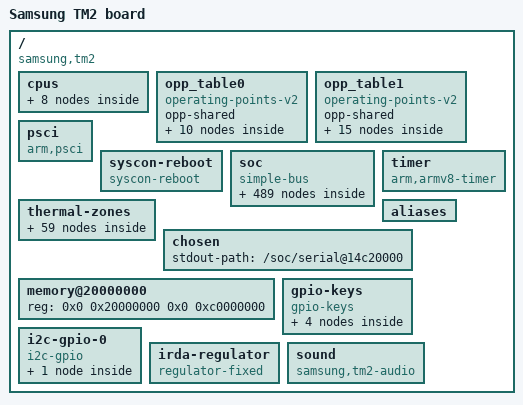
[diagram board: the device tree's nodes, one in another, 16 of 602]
/dts-v1/;

/ {
	compatible = "samsung,tm2", "samsung,exynos5433";
	#address-cells = <0x2>;
	#size-cells = <0x2>;
	interrupt-parent = <0x1>;
	model = "Samsung TM2 board";

	cpus {
		#address-cells = <0x1>;
		#size-cells = <0x0>;

		cpu@100 {
			device_type = "cpu";
			compatible = "arm,cortex-a53", "arm,armv8";
			enable-method = "psci";
			reg = <0x100>;
			clock-frequency = "M|m";
			clocks = <0x2 0x1e>;
			clock-names = "apolloclk";
			operating-points-v2 = <0x3>;
			#cooling-cells = <0x2>;
			cpu-supply = <0x4>;
			linux,phandle = <0x90>;
			phandle = <0x90>;
		};

		cpu@101 {
			device_type = "cpu";
			compatible = "arm,cortex-a53", "arm,armv8";
			enable-method = "psci";
			reg = <0x101>;
			clock-frequency = "M|m";
			operating-points-v2 = <0x3>;
			#cooling-cells = <0x2>;
			linux,phandle = <0x9b>;
			phandle = <0x9b>;
		};

		cpu@102 {
			device_type = "cpu";
			compatible = "arm,cortex-a53", "arm,armv8";
			enable-method = "psci";
			reg = <0x102>;
			clock-frequency = "M|m";
			operating-points-v2 = <0x3>;
			#cooling-cells = <0x2>;
			linux,phandle = <0x9c>;
			phandle = <0x9c>;
		};

		cpu@103 {
			device_type = "cpu";
			compatible = "arm,cortex-a53", "arm,armv8";
			enable-method = "psci";
			reg = <0x103>;
			clock-frequency = "M|m";
			operating-points-v2 = <0x3>;
			#cooling-cells = <0x2>;
			linux,phandle = <0x9d>;
			phandle = <0x9d>;
		};

		cpu@0 {
			device_type = "cpu";
			compatible = "arm,cortex-a57", "arm,armv8";
			enable-method = "psci";
			reg = <0x0>;
			clock-frequency = <0x713fb300>;
			clocks = <0x5 0x27>;
			clock-names = "atlasclk";
			operating-points-v2 = <0x6>;
			#cooling-cells = <0x2>;
			cpu-supply = <0x7>;
			linux,phandle = <0x85>;
			phandle = <0x85>;
		};

		cpu@1 {
			device_type = "cpu";
			compatible = "arm,cortex-a57", "arm,armv8";
			enable-method = "psci";
			reg = <0x1>;
			clock-frequency = <0x713fb300>;
			operating-points-v2 = <0x6>;
			#cooling-cells = <0x2>;
			linux,phandle = <0x9e>;
			phandle = <0x9e>;
		};

		cpu@2 {
			device_type = "cpu";
			compatible = "arm,cortex-a57", "arm,armv8";
			enable-method = "psci";
			reg = <0x2>;
			clock-frequency = <0x713fb300>;
			operating-points-v2 = <0x6>;
			#cooling-cells = <0x2>;
			linux,phandle = <0x9f>;
			phandle = <0x9f>;
		};

		cpu@3 {
			device_type = "cpu";
			compatible = "arm,cortex-a57", "arm,armv8";
			enable-method = "psci";
			reg = <0x3>;
			clock-frequency = <0x713fb300>;
			operating-points-v2 = <0x6>;
			#cooling-cells = <0x2>;
			linux,phandle = <0xa0>;
			phandle = <0xa0>;
		};
	};

	opp_table0 {
		compatible = "operating-points-v2";
		opp-shared;
		linux,phandle = <0x3>;
		phandle = <0x3>;

		opp-400000000 {
			opp-hz = <0x0 0x17d78400>;
			opp-microvolt = <0xdbba0>;
		};

		opp-500000000 {
			opp-hz = <0x0 0x1dcd6500>;
			opp-microvolt = <0xe1d48>;
		};

		opp-600000000 {
			opp-hz = <0x0 0x23c34600>;
			opp-microvolt = <0xe7ef0>;
		};

		opp-700000000 {
			opp-hz = <0x0 0x29b92700>;
			opp-microvolt = <0xee098>;
		};

		opp-800000000 {
			opp-hz = <0x0 0x2faf0800>;
			opp-microvolt = <0xf4240>;
		};

		opp-900000000 {
			opp-hz = <0x0 0x35a4e900>;
			opp-microvolt = <0x100590>;
		};

		opp-1000000000 {
			opp-hz = <0x0 0x3b9aca00>;
			opp-microvolt = <0x106738>;
		};

		opp-1100000000 {
			opp-hz = <0x0 0x4190ab00>;
			opp-microvolt = <0x10f9b4>;
		};

		opp-1200000000 {
			opp-hz = <0x0 0x47868c00>;
			opp-microvolt = <0x10f9b4>;
		};

		opp-1300000000 {
			opp-hz = <0x0 0x4d7c6d00>;
			opp-microvolt = <0x118c30>;
		};
	};

	opp_table1 {
		compatible = "operating-points-v2";
		opp-shared;
		linux,phandle = <0x6>;
		phandle = <0x6>;

		opp-500000000 {
			opp-hz = <0x0 0x1dcd6500>;
			opp-microvolt = <0xdbba0>;
		};

		opp-600000000 {
			opp-hz = <0x0 0x23c34600>;
			opp-microvolt = <0xdbba0>;
		};

		opp-700000000 {
			opp-hz = <0x0 0x29b92700>;
			opp-microvolt = <0xdec74>;
		};

		opp-800000000 {
			opp-hz = <0x0 0x2faf0800>;
			opp-microvolt = <0xdec74>;
		};

		opp-900000000 {
			opp-hz = <0x0 0x35a4e900>;
			opp-microvolt = <0xe4e1c>;
		};

		opp-1000000000 {
			opp-hz = <0x0 0x3b9aca00>;
			opp-microvolt = <0xee098>;
		};

		opp-1100000000 {
			opp-hz = <0x0 0x4190ab00>;
			opp-microvolt = <0xf7314>;
		};

		opp-1200000000 {
			opp-hz = <0x0 0x47868c00>;
			opp-microvolt = <0xfd4bc>;
		};

		opp-1300000000 {
			opp-hz = <0x0 0x4d7c6d00>;
			opp-microvolt = <0x103664>;
		};

		opp-1400000000 {
			opp-hz = <0x0 0x53724e00>;
			opp-microvolt = <0x10980c>;
		};

		opp-1500000000 {
			opp-hz = <0x0 0x59682f00>;
			opp-microvolt = <0x112a88>;
		};

		opp-1600000000 {
			opp-hz = <0x0 0x5f5e1000>;
			opp-microvolt = <0x115b5c>;
		};

		opp-1700000000 {
			opp-hz = <0x0 0x6553f100>;
			opp-microvolt = <0x11edd8>;
		};

		opp-1800000000 {
			opp-hz = <0x0 0x6b49d200>;
			opp-microvolt = <0x128054>;
		};

		opp-1900000000 {
			opp-hz = <0x0 0x713fb300>;
			opp-microvolt = <0x1343a4>;
		};
	};

	psci {
		compatible = "arm,psci";
		method = "smc";
		cpu_off = <0x84000002>;
		cpu_on = <0xc4000003>;
	};

	syscon-reboot {
		compatible = "syscon-reboot";
		regmap = <0x8>;
		offset = <0x400>;
		mask = <0x1>;
		linux,phandle = <0xa1>;
		phandle = <0xa1>;
	};

	soc {
		compatible = "simple-bus";
		#address-cells = <0x1>;
		#size-cells = <0x1>;
		ranges = <0x0 0x0 0x0 0x18000000>;
		linux,phandle = <0xa2>;
		phandle = <0xa2>;

		chipid@10000000 {
			compatible = "samsung,exynos4210-chipid";
			reg = <0x10000000 0x100>;
		};

		xxti {
			compatible = "fixed-clock";
			clock-output-names = "oscclk";
			#clock-cells = <0x0>;
			clock-frequency = <0x16e3600>;
			linux,phandle = <0x9>;
			phandle = <0x9>;
		};

		clock-controller@10030000 {
			compatible = "samsung,exynos5433-cmu-top";
			reg = <0x10030000 0x1000>;
			#clock-cells = <0x1>;
			clock-names = "oscclk", "sclk_mphy_pll", "sclk_mfc_pll", "sclk_bus_pll";
			clocks = <0x9 0xa 0xb 0xb 0xc5 0xb 0xc6>;
			linux,phandle = <0xc>;
			phandle = <0xc>;
		};

		clock-controller@10fc0000 {
			compatible = "samsung,exynos5433-cmu-cpif";
			reg = <0x10fc0000 0x1000>;
			#clock-cells = <0x1>;
			clock-names = "oscclk";
			clocks = <0x9>;
			linux,phandle = <0xa>;
			phandle = <0xa>;
		};

		clock-controller@105b0000 {
			compatible = "samsung,exynos5433-cmu-mif";
			reg = <0x105b0000 0x2000>;
			#clock-cells = <0x1>;
			clock-names = "oscclk", "sclk_mphy_pll";
			clocks = <0x9 0xa 0xb>;
			linux,phandle = <0xb>;
			phandle = <0xb>;
		};

		clock-controller@14c80000 {
			compatible = "samsung,exynos5433-cmu-peric";
			reg = <0x14c80000 0x1000>;
			#clock-cells = <0x1>;
			linux,phandle = <0x3c>;
			phandle = <0x3c>;
		};

		clock-controller@10040000 {
			compatible = "samsung,exynos5433-cmu-peris";
			reg = <0x10040000 0x1000>;
			#clock-cells = <0x1>;
			linux,phandle = <0x13>;
			phandle = <0x13>;
		};

		clock-controller@156e0000 {
			compatible = "samsung,exynos5433-cmu-fsys";
			reg = <0x156e0000 0x1000>;
			#clock-cells = <0x1>;
			clock-names = "oscclk", "sclk_ufs_mphy", "aclk_fsys_200", "sclk_pcie_100_fsys", "sclk_ufsunipro_fsys", "sclk_mmc2_fsys", "sclk_mmc1_fsys", "sclk_mmc0_fsys", "sclk_usbhost30_fsys", "sclk_usbdrd30_fsys";
			clocks = <0x9 0xa 0xb 0xc 0xca 0xc 0xe4 0xc 0xe5 0xc 0xcb 0xc 0xcc 0xc 0xcd 0xc 0xe6 0xc 0xe7>;
			assigned-clocks = <0xc 0x3b 0xc 0x3a 0xd 0x9 0xd 0x8 0xd 0x10 0xd 0xa 0xd 0x11 0xd 0xb 0xc 0x8f 0xc 0x8d>;
			assigned-clock-parents = <0xc 0xf 0xc 0xf 0xc 0xe7 0xc 0xe6 0xd 0x1a 0xd 0x1c 0xd 0x19 0xd 0x1b>;
			assigned-clock-rates = <0x0 0x0 0x0 0x0 0x0 0x0 0x0 0x0 0x3f9c2e0 0x3f9c2e0>;
			linux,phandle = <0xd>;
			phandle = <0xd>;
		};

		clock-controller@12460000 {
			compatible = "samsung,exynos5433-cmu-g2d";
			reg = <0x12460000 0x1000>;
			#clock-cells = <0x1>;
			clock-names = "oscclk", "aclk_g2d_266", "aclk_g2d_400";
			clocks = <0x9 0xc 0xdc 0xc 0xdd>;
			linux,phandle = <0xa3>;
			phandle = <0xa3>;
		};

		clock-controller@13b90000 {
			compatible = "samsung,exynos5433-cmu-disp";
			reg = <0x13b90000 0x1000>;
			#clock-cells = <0x1>;
			clock-names = "oscclk", "sclk_dsim1_disp", "sclk_dsim0_disp", "sclk_dsd_disp", "sclk_decon_tv_eclk_disp", "sclk_decon_vclk_disp", "sclk_decon_eclk_disp", "sclk_decon_tv_vclk_disp", "aclk_disp_333";
			clocks = <0x9 0xb 0xb9 0xb 0xbf 0xb 0xc0 0xb 0xc1 0xb 0xc2 0xb 0xc3 0xb 0xba 0xb 0x98>;
			assigned-clocks = <0xe 0x1 0xb 0x48 0xe 0xa 0xe 0x4 0xe 0x11 0xe 0x8 0xe 0x14 0xe 0xe 0xe 0xd 0xe 0x2 0xb 0x24 0xe 0x6 0xe 0x12>;
			assigned-clock-parents = <0x0 0x0 0xb 0x98 0xb 0xbf 0xe 0x4 0xb 0xc3 0xe 0x8 0xe 0x73 0xe 0x72 0xe 0x1 0xb 0xb 0xb 0xc1 0xe 0x6>;
			assigned-clock-rates = <0xee6b280 0x17d78400>;
			linux,phandle = <0xe>;
			phandle = <0xe>;
		};

		clock-controller@114c0000 {
			compatible = "samsung,exynos5433-cmu-aud";
			reg = <0x114c0000 0x1000>;
			#clock-cells = <0x1>;
			clock-names = "oscclk", "fout_aud_pll";
			clocks = <0x9 0xc 0x2>;
			assigned-clocks = <0xf 0x1>;
			assigned-clock-parents = <0xc 0x2>;
			linux,phandle = <0xf>;
			phandle = <0xf>;
		};

		clock-controller@13600000 {
			compatible = "samsung,exynos5433-cmu-bus0";
			reg = <0x13600000 0x1000>;
			#clock-cells = <0x1>;
			clock-names = "aclk_bus0_400";
			clocks = <0xc 0xe0>;
			linux,phandle = <0xa4>;
			phandle = <0xa4>;
		};

		clock-controller@14800000 {
			compatible = "samsung,exynos5433-cmu-bus1";
			reg = <0x14800000 0x1000>;
			#clock-cells = <0x1>;
			clock-names = "aclk_bus1_400";
			clocks = <0xc 0xe1>;
			linux,phandle = <0xa5>;
			phandle = <0xa5>;
		};

		clock-controller@13400000 {
			compatible = "samsung,exynos5433-cmu-bus2";
			reg = <0x13400000 0x1000>;
			#clock-cells = <0x1>;
			clock-names = "oscclk", "aclk_bus2_400";
			clocks = <0x9 0xb 0x97>;
			linux,phandle = <0xa6>;
			phandle = <0xa6>;
		};

		clock-controller@14aa0000 {
			compatible = "samsung,exynos5433-cmu-g3d";
			reg = <0x14aa0000 0x2000>;
			#clock-cells = <0x1>;
			clock-names = "oscclk", "aclk_g3d_400";
			clocks = <0x9 0xc 0xde>;
			linux,phandle = <0xa7>;
			phandle = <0xa7>;
		};

		clock-controller@13cf0000 {
			compatible = "samsung,exynos5433-cmu-gscl";
			reg = <0x13cf0000 0x1000>;
			#clock-cells = <0x1>;
			clock-names = "oscclk", "aclk_gscl_111", "aclk_gscl_333";
			clocks = <0x9 0xc 0xe8 0xc 0xe9>;
			assigned-clocks = <0x10 0x1 0x10 0x2>;
			assigned-clock-parents = <0xc 0xe8 0xc 0xe9>;
			linux,phandle = <0x10>;
			phandle = <0x10>;
		};

		clock-controller@11900000 {
			compatible = "samsung,exynos5433-cmu-apollo";
			reg = <0x11900000 0x2000>;
			#clock-cells = <0x1>;
			clock-names = "oscclk", "sclk_bus_pll_apollo";
			clocks = <0x9 0xb 0xc7>;
			linux,phandle = <0x2>;
			phandle = <0x2>;
		};

		clock-controller@11800000 {
			compatible = "samsung,exynos5433-cmu-atlas";
			reg = <0x11800000 0x2000>;
			#clock-cells = <0x1>;
			clock-names = "oscclk", "sclk_bus_pll_atlas";
			clocks = <0x9 0xb 0xc8>;
			linux,phandle = <0x5>;
			phandle = <0x5>;
		};

		clock-controller@105d0000 {
			compatible = "samsung,exynos5433-cmu-mscl";
			reg = <0x150d0000 0x1000>;
			#clock-cells = <0x1>;
			clock-names = "oscclk", "sclk_jpeg_mscl", "aclk_mscl_400";
			clocks = <0x9 0xc 0xea 0xc 0xeb>;
			assigned-clocks = <0x11 0x2 0x11 0x1 0x11 0x3 0xc 0x1e>;
			assigned-clock-parents = <0xc 0xeb 0xc 0xea 0x11 0x1 0xc 0xf>;
			linux,phandle = <0x11>;
			phandle = <0x11>;
		};

		clock-controller@15280000 {
			compatible = "samsung,exynos5433-cmu-mfc";
			reg = <0x15280000 0x1000>;
			#clock-cells = <0x1>;
			clock-names = "oscclk", "aclk_mfc_400";
			clocks = <0x9 0xc 0xec>;
			assigned-clocks = <0x12 0x1>;
			assigned-clock-parents = <0xc 0xec>;
			linux,phandle = <0x12>;
			phandle = <0x12>;
		};

		clock-controller@14f80000 {
			compatible = "samsung,exynos5433-cmu-hevc";
			reg = <0x14f80000 0x1000>;
			#clock-cells = <0x1>;
			clock-names = "oscclk", "aclk_hevc_400";
			clocks = <0x9 0xc 0xed>;
			linux,phandle = <0xa8>;
			phandle = <0xa8>;
		};

		clock-controller@146d0000 {
			compatible = "samsung,exynos5433-cmu-isp";
			reg = <0x146d0000 0x1000>;
			#clock-cells = <0x1>;
			clock-names = "oscclk", "aclk_isp_dis_400", "aclk_isp_400";
			clocks = <0x9 0xc 0xee 0xc 0xef>;
			linux,phandle = <0xa9>;
			phandle = <0xa9>;
		};

		clock-controller@120d0000 {
			compatible = "samsung,exynos5433-cmu-cam0";
			reg = <0x120d0000 0x1000>;
			#clock-cells = <0x1>;
			clock-names = "oscclk", "aclk_cam0_333", "aclk_cam0_400", "aclk_cam0_552";
			clocks = <0x9 0xc 0xf0 0xc 0xf1 0xc 0xf2>;
			linux,phandle = <0xaa>;
			phandle = <0xaa>;
		};

		clock-controller@145d0000 {
			compatible = "samsung,exynos5433-cmu-cam1";
			reg = <0x145d0000 0x1000>;
			#clock-cells = <0x1>;
			clock-names = "oscclk", "sclk_isp_uart_cam1", "sclk_isp_spi1_cam1", "sclk_isp_spi0_cam1", "aclk_cam1_333", "aclk_cam1_400", "aclk_cam1_552";
			clocks = <0x9 0xc 0xfa 0xc 0xfb 0xc 0xfc 0xc 0xf3 0xc 0xf4 0xc 0xf5>;
			linux,phandle = <0xab>;
			phandle = <0xab>;
		};

		tmu@10060000 {
			compatible = "samsung,exynos5433-tmu";
			reg = <0x10060000 0x200>;
			interrupts = <0x0 0x5f 0x4>;
			clocks = <0x13 0x3 0x13 0x23>;
			clock-names = "tmu_apbif", "tmu_sclk";
			#thermal-sensor-cells = <0x0>;
			samsung,tmu_gain = <0x8>;
			samsung,tmu_reference_voltage = <0x10>;
			samsung,tmu_noise_cancel_mode = <0x4>;
			samsung,tmu_efuse_value = <0x4b>;
			samsung,tmu_min_efuse_value = <0x28>;
			samsung,tmu_max_efuse_value = <0x96>;
			samsung,tmu_first_point_trim = <0x19>;
			samsung,tmu_second_point_trim = <0x55>;
			samsung,tmu_default_temp_offset = <0x32>;
			status = "okay";
			vtmu-supply = <0x14>;
			linux,phandle = <0x83>;
			phandle = <0x83>;
		};

		tmu@10068000 {
			compatible = "samsung,exynos5433-tmu";
			reg = <0x10068000 0x200>;
			interrupts = <0x0 0x60 0x4>;
			clocks = <0x13 0x3 0x13 0x23>;
			clock-names = "tmu_apbif", "tmu_sclk";
			#thermal-sensor-cells = <0x0>;
			samsung,tmu_gain = <0x8>;
			samsung,tmu_reference_voltage = <0x10>;
			samsung,tmu_noise_cancel_mode = <0x4>;
			samsung,tmu_efuse_value = <0x4b>;
			samsung,tmu_min_efuse_value = <0x28>;
			samsung,tmu_max_efuse_value = <0x96>;
			samsung,tmu_first_point_trim = <0x19>;
			samsung,tmu_second_point_trim = <0x55>;
			samsung,tmu_default_temp_offset = <0x32>;
			status = "disabled";
			linux,phandle = <0x8c>;
			phandle = <0x8c>;
		};

		tmu@10070000 {
			compatible = "samsung,exynos5433-tmu";
			reg = <0x10070000 0x200>;
			interrupts = <0x0 0x63 0x4>;
			clocks = <0x13 0x2 0x13 0x22>;
			clock-names = "tmu_apbif", "tmu_sclk";
			#thermal-sensor-cells = <0x0>;
			samsung,tmu_gain = <0x8>;
			samsung,tmu_reference_voltage = <0x17>;
			samsung,tmu_noise_cancel_mode = <0x4>;
			samsung,tmu_efuse_value = <0x4b>;
			samsung,tmu_min_efuse_value = <0x28>;
			samsung,tmu_max_efuse_value = <0x96>;
			samsung,tmu_first_point_trim = <0x19>;
			samsung,tmu_second_point_trim = <0x55>;
			samsung,tmu_default_temp_offset = <0x32>;
			samsung,tmu_mux_addr = <0x6>;
			status = "okay";
			vtmu-supply = <0x14>;
			linux,phandle = <0x8d>;
			phandle = <0x8d>;
		};

		tmu@10078000 {
			compatible = "samsung,exynos5433-tmu";
			reg = <0x10078000 0x200>;
			interrupts = <0x0 0x73 0x4>;
			clocks = <0x13 0x2 0x13 0x22>;
			clock-names = "tmu_apbif", "tmu_sclk";
			#thermal-sensor-cells = <0x0>;
			samsung,tmu_gain = <0x8>;
			samsung,tmu_reference_voltage = <0x10>;
			samsung,tmu_noise_cancel_mode = <0x4>;
			samsung,tmu_efuse_value = <0x4b>;
			samsung,tmu_min_efuse_value = <0x28>;
			samsung,tmu_max_efuse_value = <0x96>;
			samsung,tmu_first_point_trim = <0x19>;
			samsung,tmu_second_point_trim = <0x55>;
			samsung,tmu_default_temp_offset = <0x32>;
			status = "okay";
			vtmu-supply = <0x14>;
			linux,phandle = <0x8e>;
			phandle = <0x8e>;
		};

		tmu@1007c000 {
			compatible = "samsung,exynos5433-tmu";
			reg = <0x1007c000 0x200>;
			interrupts = <0x0 0x5e 0x4>;
			clocks = <0x13 0x2 0x13 0x22>;
			clock-names = "tmu_apbif", "tmu_sclk";
			#thermal-sensor-cells = <0x0>;
			samsung,tmu_gain = <0x8>;
			samsung,tmu_reference_voltage = <0x10>;
			samsung,tmu_noise_cancel_mode = <0x4>;
			samsung,tmu_efuse_value = <0x4b>;
			samsung,tmu_min_efuse_value = <0x28>;
			samsung,tmu_max_efuse_value = <0x96>;
			samsung,tmu_first_point_trim = <0x19>;
			samsung,tmu_second_point_trim = <0x55>;
			samsung,tmu_default_temp_offset = <0x32>;
			status = "disabled";
			linux,phandle = <0x95>;
			phandle = <0x95>;
		};

		mct@101c0000 {
			compatible = "samsung,exynos4210-mct";
			reg = <0x101c0000 0x800>;
			interrupts = <0x0 0x66 0x4 0x0 0x67 0x4 0x0 0x68 0x4 0x0 0x69 0x4 0x0 0x6a 0x4 0x0 0x6b 0x4 0x0 0x6c 0x4 0x0 0x6d 0x4 0x0 0x6e 0x4 0x0 0x6f 0x4 0x0 0x70 0x4 0x0 0x71 0x4>;
			clocks = <0x9 0x13 0x9>;
			clock-names = "fin_pll", "mct";
		};

		ppmu@10480000 {
			compatible = "samsung,exynos-ppmu-v2";
			reg = <0x10480000 0x2000>;
			status = "disabled";
			linux,phandle = <0xac>;
			phandle = <0xac>;
		};

		ppmu@10490000 {
			compatible = "samsung,exynos-ppmu-v2";
			reg = <0x10490000 0x2000>;
			status = "okay";
			linux,phandle = <0xad>;
			phandle = <0xad>;

			events {

				ppmu-event0-d0-general {
					event-name = "ppmu-event0-d0-general";
					linux,phandle = <0x7b>;
					phandle = <0x7b>;
				};
			};
		};

		ppmu@104b0000 {
			compatible = "samsung,exynos-ppmu-v2";
			reg = <0x104b0000 0x2000>;
			status = "disabled";
			linux,phandle = <0xae>;
			phandle = <0xae>;
		};

		ppmu@104c0000 {
			compatible = "samsung,exynos-ppmu-v2";
			reg = <0x104c0000 0x2000>;
			status = "okay";
			linux,phandle = <0xaf>;
			phandle = <0xaf>;

			events {

				ppmu-event0-d1-general {
					event-name = "ppmu-event0-d1-general";
					linux,phandle = <0x7c>;
					phandle = <0x7c>;
				};
			};
		};

		pinctrl@10580000 {
			compatible = "samsung,exynos5433-pinctrl";
			reg = <0x10580000 0x1a20 0x11090000 0x100>;
			pinctrl-names = "default";
			pinctrl-0 = <0x15>;
			linux,phandle = <0xb0>;
			phandle = <0xb0>;

			wakeup-interrupt-controller {
				compatible = "samsung,exynos7-wakeup-eint";
				interrupts = <0x0 0x10 0x4>;
			};

			gpa0 {
				gpio-controller;
				#gpio-cells = <0x2>;
				interrupt-controller;
				interrupt-parent = <0x1>;
				interrupts = <0x0 0x0 0x4 0x0 0x1 0x4 0x0 0x2 0x4 0x0 0x3 0x4 0x0 0x4 0x4 0x0 0x5 0x4 0x0 0x6 0x4 0x0 0x7 0x4>;
				#interrupt-cells = <0x2>;
				linux,phandle = <0x44>;
				phandle = <0x44>;
			};

			gpa1 {
				gpio-controller;
				#gpio-cells = <0x2>;
				interrupt-controller;
				interrupt-parent = <0x1>;
				interrupts = <0x0 0x8 0x4 0x0 0x9 0x4 0x0 0xa 0x4 0x0 0xb 0x4 0x0 0xc 0x4 0x0 0xd 0x4 0x0 0xe 0x4 0x0 0xf 0x4>;
				#interrupt-cells = <0x2>;
				linux,phandle = <0x55>;
				phandle = <0x55>;
			};

			gpa2 {
				gpio-controller;
				#gpio-cells = <0x2>;
				interrupt-controller;
				#interrupt-cells = <0x2>;
				linux,phandle = <0x72>;
				phandle = <0x72>;
			};

			gpa3 {
				gpio-controller;
				#gpio-cells = <0x2>;
				interrupt-controller;
				#interrupt-cells = <0x2>;
				linux,phandle = <0x33>;
				phandle = <0x33>;
			};

			gpf1 {
				gpio-controller;
				#gpio-cells = <0x2>;
				interrupt-controller;
				#interrupt-cells = <0x2>;
				linux,phandle = <0x2e>;
				phandle = <0x2e>;
			};

			gpf2 {
				gpio-controller;
				#gpio-cells = <0x2>;
				interrupt-controller;
				#interrupt-cells = <0x2>;
				linux,phandle = <0xb1>;
				phandle = <0xb1>;
			};

			gpf3 {
				gpio-controller;
				#gpio-cells = <0x2>;
				interrupt-controller;
				#interrupt-cells = <0x2>;
				linux,phandle = <0xb2>;
				phandle = <0xb2>;
			};

			gpf4 {
				gpio-controller;
				#gpio-cells = <0x2>;
				interrupt-controller;
				#interrupt-cells = <0x2>;
				linux,phandle = <0xb3>;
				phandle = <0xb3>;
			};

			gpf5 {
				gpio-controller;
				#gpio-cells = <0x2>;
				interrupt-controller;
				#interrupt-cells = <0x2>;
				linux,phandle = <0xb4>;
				phandle = <0xb4>;
			};

			initial-state {
				linux,phandle = <0x15>;
				phandle = <0x15>;

				gpa0-0 {
					samsung,pins = "gpa0-0";
					samsung,pin-function = <0x0>;
					samsung,pin-pud = <0x1>;
					samsung,pin-drv = <0x0>;
				};

				gpa0-1 {
					samsung,pins = "gpa0-1";
					samsung,pin-function = <0x0>;
					samsung,pin-pud = <0x0>;
					samsung,pin-drv = <0x0>;
				};

				gpa0-2 {
					samsung,pins = "gpa0-2";
					samsung,pin-function = <0x0>;
					samsung,pin-pud = <0x1>;
					samsung,pin-drv = <0x0>;
				};

				gpa0-3 {
					samsung,pins = "gpa0-3";
					samsung,pin-function = <0x0>;
					samsung,pin-pud = <0x0>;
					samsung,pin-drv = <0x0>;
				};

				gpa0-4 {
					samsung,pins = "gpa0-4";
					samsung,pin-function = <0x0>;
					samsung,pin-pud = <0x0>;
					samsung,pin-drv = <0x0>;
				};

				gpa0-5 {
					samsung,pins = "gpa0-5";
					samsung,pin-function = <0x0>;
					samsung,pin-pud = <0x1>;
					samsung,pin-drv = <0x0>;
				};

				gpa0-6 {
					samsung,pins = "gpa0-6";
					samsung,pin-function = <0x0>;
					samsung,pin-pud = <0x0>;
					samsung,pin-drv = <0x0>;
				};

				gpa0-7 {
					samsung,pins = "gpa0-7";
					samsung,pin-function = <0x0>;
					samsung,pin-pud = <0x0>;
					samsung,pin-drv = <0x0>;
				};

				gpa1-0 {
					samsung,pins = "gpa1-0";
					samsung,pin-function = <0x0>;
					samsung,pin-pud = <0x3>;
					samsung,pin-drv = <0x0>;
				};

				gpa1-1 {
					samsung,pins = "gpa1-1";
					samsung,pin-function = <0x0>;
					samsung,pin-pud = <0x3>;
					samsung,pin-drv = <0x0>;
				};

				gpa1-2 {
					samsung,pins = "gpa1-2";
					samsung,pin-function = <0x0>;
					samsung,pin-pud = <0x0>;
					samsung,pin-drv = <0x0>;
				};

				gpa1-3 {
					samsung,pins = "gpa1-3";
					samsung,pin-function = <0x0>;
					samsung,pin-pud = <0x1>;
					samsung,pin-drv = <0x0>;
				};

				gpa1-4 {
					samsung,pins = "gpa1-4";
					samsung,pin-function = <0x0>;
					samsung,pin-pud = <0x1>;
					samsung,pin-drv = <0x0>;
				};

				gpa1-5 {
					samsung,pins = "gpa1-5";
					samsung,pin-function = <0x0>;
					samsung,pin-pud = <0x0>;
					samsung,pin-drv = <0x0>;
				};

				gpa1-6 {
					samsung,pins = "gpa1-6";
					samsung,pin-function = <0x0>;
					samsung,pin-pud = <0x0>;
					samsung,pin-drv = <0x0>;
				};

				gpa1-7 {
					samsung,pins = "gpa1-7";
					samsung,pin-function = <0x0>;
					samsung,pin-pud = <0x0>;
					samsung,pin-drv = <0x0>;
				};

				gpa2-0 {
					samsung,pins = "gpa2-0";
					samsung,pin-function = <0x0>;
					samsung,pin-pud = <0x0>;
					samsung,pin-drv = <0x0>;
				};

				gpa2-1 {
					samsung,pins = "gpa2-1";
					samsung,pin-function = <0x0>;
					samsung,pin-pud = <0x0>;
					samsung,pin-drv = <0x0>;
				};

				gpa2-2 {
					samsung,pins = "gpa2-2";
					samsung,pin-function = <0x0>;
					samsung,pin-pud = <0x0>;
					samsung,pin-drv = <0x0>;
				};

				gpa2-3 {
					samsung,pins = "gpa2-3";
					samsung,pin-function = <0x0>;
					samsung,pin-pud = <0x1>;
					samsung,pin-drv = <0x0>;
				};

				gpa2-4 {
					samsung,pins = "gpa2-4";
					samsung,pin-function = <0x0>;
					samsung,pin-pud = <0x0>;
					samsung,pin-drv = <0x0>;
				};

				gpa2-5 {
					samsung,pins = "gpa2-5";
					samsung,pin-function = <0x0>;
					samsung,pin-pud = <0x1>;
					samsung,pin-drv = <0x0>;
				};

				gpa2-6 {
					samsung,pins = "gpa2-6";
					samsung,pin-function = <0x0>;
					samsung,pin-pud = <0x1>;
					samsung,pin-drv = <0x0>;
				};

				gpa2-7 {
					samsung,pins = "gpa2-7";
					samsung,pin-function = <0x0>;
					samsung,pin-pud = <0x0>;
					samsung,pin-drv = <0x0>;
				};

				gpa3-0 {
					samsung,pins = "gpa3-0";
					samsung,pin-function = <0x0>;
					samsung,pin-pud = <0x1>;
					samsung,pin-drv = <0x0>;
				};

				gpa3-1 {
					samsung,pins = "gpa3-1";
					samsung,pin-function = <0x0>;
					samsung,pin-pud = <0x1>;
					samsung,pin-drv = <0x0>;
				};

				gpa3-2 {
					samsung,pins = "gpa3-2";
					samsung,pin-function = <0x0>;
					samsung,pin-pud = <0x0>;
					samsung,pin-drv = <0x0>;
				};

				gpa3-3 {
					samsung,pins = "gpa3-3";
					samsung,pin-function = <0x0>;
					samsung,pin-pud = <0x1>;
					samsung,pin-drv = <0x0>;
				};

				gpa3-4 {
					samsung,pins = "gpa3-4";
					samsung,pin-function = <0x0>;
					samsung,pin-pud = <0x0>;
					samsung,pin-drv = <0x0>;
				};

				gpa3-5 {
					samsung,pins = "gpa3-5";
					samsung,pin-function = <0x0>;
					samsung,pin-pud = <0x1>;
					samsung,pin-drv = <0x0>;
				};

				gpa3-6 {
					samsung,pins = "gpa3-6";
					samsung,pin-function = <0x0>;
					samsung,pin-pud = <0x1>;
					samsung,pin-drv = <0x0>;
				};

				gpa3-7 {
					samsung,pins = "gpa3-7";
					samsung,pin-function = <0x0>;
					samsung,pin-pud = <0x1>;
					samsung,pin-drv = <0x0>;
				};

				gpf1-0 {
					samsung,pins = "gpf1-0";
					samsung,pin-function = <0x0>;
					samsung,pin-pud = <0x0>;
					samsung,pin-drv = <0x0>;
				};

				gpf1-1 {
					samsung,pins = "gpf1-1";
					samsung,pin-function = <0x0>;
					samsung,pin-pud = <0x0>;
					samsung,pin-drv = <0x0>;
				};

				gpf1-2 {
					samsung,pins = "gpf1-2";
					samsung,pin-function = <0x0>;
					samsung,pin-pud = <0x1>;
					samsung,pin-drv = <0x0>;
				};

				gpf1-4 {
					samsung,pins = "gpf1-4";
					samsung,pin-function = <0x0>;
					samsung,pin-pud = <0x3>;
					samsung,pin-drv = <0x0>;
				};

				gpf1-5 {
					samsung,pins = "gpf1-5";
					samsung,pin-function = <0x1>;
					samsung,pin-pud = <0x0>;
					samsung,pin-drv = <0x0>;
				};

				gpf1-6 {
					samsung,pins = "gpf1-6";
					samsung,pin-function = <0x0>;
					samsung,pin-pud = <0x1>;
					samsung,pin-drv = <0x0>;
				};

				gpf1-7 {
					samsung,pins = "gpf1-7";
					samsung,pin-function = <0x0>;
					samsung,pin-pud = <0x1>;
					samsung,pin-drv = <0x0>;
				};

				gpf2-0 {
					samsung,pins = "gpf2-0";
					samsung,pin-function = <0x0>;
					samsung,pin-pud = <0x1>;
					samsung,pin-drv = <0x0>;
				};

				gpf2-1 {
					samsung,pins = "gpf2-1";
					samsung,pin-function = <0x0>;
					samsung,pin-pud = <0x1>;
					samsung,pin-drv = <0x0>;
				};

				gpf2-2 {
					samsung,pins = "gpf2-2";
					samsung,pin-function = <0x0>;
					samsung,pin-pud = <0x1>;
					samsung,pin-drv = <0x0>;
				};

				gpf2-3 {
					samsung,pins = "gpf2-3";
					samsung,pin-function = <0x0>;
					samsung,pin-pud = <0x1>;
					samsung,pin-drv = <0x0>;
				};

				gpf3-0 {
					samsung,pins = "gpf3-0";
					samsung,pin-function = <0x0>;
					samsung,pin-pud = <0x1>;
					samsung,pin-drv = <0x0>;
				};

				gpf3-1 {
					samsung,pins = "gpf3-1";
					samsung,pin-function = <0x0>;
					samsung,pin-pud = <0x1>;
					samsung,pin-drv = <0x0>;
				};

				gpf3-2 {
					samsung,pins = "gpf3-2";
					samsung,pin-function = <0x0>;
					samsung,pin-pud = <0x0>;
					samsung,pin-drv = <0x0>;
				};

				gpf3-3 {
					samsung,pins = "gpf3-3";
					samsung,pin-function = <0x0>;
					samsung,pin-pud = <0x1>;
					samsung,pin-drv = <0x0>;
				};

				gpf4-0 {
					samsung,pins = "gpf4-0";
					samsung,pin-function = <0x0>;
					samsung,pin-pud = <0x1>;
					samsung,pin-drv = <0x0>;
				};

				gpf4-1 {
					samsung,pins = "gpf4-1";
					samsung,pin-function = <0x0>;
					samsung,pin-pud = <0x1>;
					samsung,pin-drv = <0x0>;
				};

				gpf4-2 {
					samsung,pins = "gpf4-2";
					samsung,pin-function = <0x0>;
					samsung,pin-pud = <0x1>;
					samsung,pin-drv = <0x0>;
				};

				gpf4-3 {
					samsung,pins = "gpf4-3";
					samsung,pin-function = <0x0>;
					samsung,pin-pud = <0x1>;
					samsung,pin-drv = <0x0>;
				};

				gpf4-4 {
					samsung,pins = "gpf4-4";
					samsung,pin-function = <0x0>;
					samsung,pin-pud = <0x1>;
					samsung,pin-drv = <0x0>;
				};

				gpf4-5 {
					samsung,pins = "gpf4-5";
					samsung,pin-function = <0x0>;
					samsung,pin-pud = <0x1>;
					samsung,pin-drv = <0x0>;
				};

				gpf4-6 {
					samsung,pins = "gpf4-6";
					samsung,pin-function = <0x0>;
					samsung,pin-pud = <0x1>;
					samsung,pin-drv = <0x0>;
				};

				gpf4-7 {
					samsung,pins = "gpf4-7";
					samsung,pin-function = <0x0>;
					samsung,pin-pud = <0x1>;
					samsung,pin-drv = <0x0>;
				};

				gpf5-0 {
					samsung,pins = "gpf5-0";
					samsung,pin-function = <0x0>;
					samsung,pin-pud = <0x1>;
					samsung,pin-drv = <0x0>;
				};

				gpf5-1 {
					samsung,pins = "gpf5-1";
					samsung,pin-function = <0x0>;
					samsung,pin-pud = <0x1>;
					samsung,pin-drv = <0x0>;
				};

				gpf5-2 {
					samsung,pins = "gpf5-2";
					samsung,pin-function = <0x0>;
					samsung,pin-pud = <0x1>;
					samsung,pin-drv = <0x0>;
				};

				gpf5-3 {
					samsung,pins = "gpf5-3";
					samsung,pin-function = <0x0>;
					samsung,pin-pud = <0x1>;
					samsung,pin-drv = <0x0>;
				};

				gpf5-4 {
					samsung,pins = "gpf5-4";
					samsung,pin-function = <0x1>;
					samsung,pin-pud = <0x0>;
					samsung,pin-drv = <0x0>;
				};

				gpf5-5 {
					samsung,pins = "gpf5-5";
					samsung,pin-function = <0x0>;
					samsung,pin-pud = <0x1>;
					samsung,pin-drv = <0x0>;
				};

				gpf5-6 {
					samsung,pins = "gpf5-6";
					samsung,pin-function = <0x0>;
					samsung,pin-pud = <0x1>;
					samsung,pin-drv = <0x0>;
				};

				gpf5-7 {
					samsung,pins = "gpf5-7";
					samsung,pin-function = <0x0>;
					samsung,pin-pud = <0x1>;
					samsung,pin-drv = <0x0>;
				};
			};

			te_irq {
				samsung,pins = "gpf1-3";
				samsung,pin-function = <0xf>;
				linux,phandle = <0x29>;
				phandle = <0x29>;
			};
		};

		pinctrl@114b0000 {
			compatible = "samsung,exynos5433-pinctrl";
			reg = <0x114b0000 0x1000>;
			interrupts = <0x0 0x44 0x4>;
			linux,phandle = <0xb5>;
			phandle = <0xb5>;

			gpz0 {
				gpio-controller;
				#gpio-cells = <0x2>;
				interrupt-controller;
				#interrupt-cells = <0x2>;
				linux,phandle = <0xb6>;
				phandle = <0xb6>;
			};

			gpz1 {
				gpio-controller;
				#gpio-cells = <0x2>;
				interrupt-controller;
				#interrupt-cells = <0x2>;
				linux,phandle = <0xb7>;
				phandle = <0xb7>;
			};

			i2s0-bus {
				samsung,pins = "gpz0-0", "gpz0-1", "gpz0-2", "gpz0-3", "gpz0-4", "gpz0-5", "gpz0-6";
				samsung,pin-function = <0x2>;
				samsung,pin-pud = <0x0>;
				samsung,pin-drv = <0x0>;
				linux,phandle = <0x78>;
				phandle = <0x78>;
			};

			pcm0-bus {
				samsung,pins = "gpz1-0", "gpz1-1", "gpz1-2", "gpz1-3";
				samsung,pin-function = <0x3>;
				samsung,pin-pud = <0x0>;
				samsung,pin-drv = <0x0>;
				linux,phandle = <0xb8>;
				phandle = <0xb8>;
			};

			uart-aud-bus {
				samsung,pins = "gpz1-3", "gpz1-2", "gpz1-1", "gpz1-0";
				samsung,pin-function = <0x2>;
				samsung,pin-pud = <0x0>;
				samsung,pin-drv = <0x0>;
				linux,phandle = <0x79>;
				phandle = <0x79>;
			};
		};

		pinctrl@10fe0000 {
			compatible = "samsung,exynos5433-pinctrl";
			reg = <0x10fe0000 0x1000>;
			interrupts = <0x0 0xb3 0x4>;
			pinctrl-names = "default";
			pinctrl-0 = <0x16>;
			linux,phandle = <0xb9>;
			phandle = <0xb9>;

			gpv6 {
				gpio-controller;
				#gpio-cells = <0x2>;
				interrupt-controller;
				#interrupt-cells = <0x2>;
				linux,phandle = <0xba>;
				phandle = <0xba>;
			};

			initial-state {
				linux,phandle = <0x16>;
				phandle = <0x16>;

				gpv6-0 {
					samsung,pins = "gpv6-0";
					samsung,pin-function = <0x0>;
					samsung,pin-pud = <0x1>;
					samsung,pin-drv = <0x0>;
				};

				gpv6-1 {
					samsung,pins = "gpv6-1";
					samsung,pin-function = <0x0>;
					samsung,pin-pud = <0x1>;
					samsung,pin-drv = <0x0>;
				};
			};
		};

		pinctrl@14ca0000 {
			compatible = "samsung,exynos5433-pinctrl";
			reg = <0x14ca0000 0x1000>;
			interrupts = <0x0 0x19d 0x4>;
			pinctrl-names = "default";
			pinctrl-0 = <0x17>;
			linux,phandle = <0xbb>;
			phandle = <0xbb>;

			gpj2 {
				gpio-controller;
				#gpio-cells = <0x2>;
				interrupt-controller;
				#interrupt-cells = <0x2>;
				linux,phandle = <0xbc>;
				phandle = <0xbc>;
			};

			initial-state {
				linux,phandle = <0x17>;
				phandle = <0x17>;

				gpj2-0 {
					samsung,pins = "gpj2-0";
					samsung,pin-function = <0x0>;
					samsung,pin-pud = <0x1>;
					samsung,pin-drv = <0x0>;
				};

				gpj2-1 {
					samsung,pins = "gpj2-1";
					samsung,pin-function = <0x0>;
					samsung,pin-pud = <0x1>;
					samsung,pin-drv = <0x0>;
				};

				gpj2-2 {
					samsung,pins = "gpj2-2";
					samsung,pin-function = <0x0>;
					samsung,pin-pud = <0x1>;
					samsung,pin-drv = <0x0>;
				};
			};
		};

		pinctrl@14cb0000 {
			compatible = "samsung,exynos5433-pinctrl";
			reg = <0x14cb0000 0x1000>;
			interrupts = <0x0 0x19e 0x4>;
			linux,phandle = <0xbd>;
			phandle = <0xbd>;

			gpd5 {
				gpio-controller;
				#gpio-cells = <0x2>;
				interrupt-controller;
				#interrupt-cells = <0x2>;
				linux,phandle = <0xbe>;
				phandle = <0xbe>;
			};

			spi2-bus {
				samsung,pins = "gpd5-0", "gpd5-2", "gpd5-3";
				samsung,pin-function = <0x2>;
				samsung,pin-pud = <0x3>;
				samsung,pin-drv = <0x0>;
				linux,phandle = <0x49>;
				phandle = <0x49>;
			};

			hs-i2c6-bus {
				samsung,pins = "gpd5-3", "gpd5-2";
				samsung,pin-function = <0x4>;
				samsung,pin-pud = <0x3>;
				samsung,pin-drv = <0x0>;
				linux,phandle = <0x58>;
				phandle = <0x58>;
			};
		};

		pinctrl@15690000 {
			compatible = "samsung,exynos5433-pinctrl";
			reg = <0x15690000 0x1000>;
			interrupts = <0x0 0xe5 0x4>;
			pinctrl-names = "default";
			pinctrl-0 = <0x18>;
			linux,phandle = <0xbf>;
			phandle = <0xbf>;

			gph1 {
				gpio-controller;
				#gpio-cells = <0x2>;
				interrupt-controller;
				#interrupt-cells = <0x2>;
				linux,phandle = <0xc0>;
				phandle = <0xc0>;
			};

			gpr4 {
				gpio-controller;
				#gpio-cells = <0x2>;
				interrupt-controller;
				#interrupt-cells = <0x2>;
				linux,phandle = <0xc1>;
				phandle = <0xc1>;
			};

			gpr0 {
				gpio-controller;
				#gpio-cells = <0x2>;
				interrupt-controller;
				#interrupt-cells = <0x2>;
				linux,phandle = <0xc2>;
				phandle = <0xc2>;
			};

			gpr1 {
				gpio-controller;
				#gpio-cells = <0x2>;
				interrupt-controller;
				#interrupt-cells = <0x2>;
				linux,phandle = <0xc3>;
				phandle = <0xc3>;
			};

			gpr2 {
				gpio-controller;
				#gpio-cells = <0x2>;
				interrupt-controller;
				#interrupt-cells = <0x2>;
				linux,phandle = <0xc4>;
				phandle = <0xc4>;
			};

			gpr3 {
				gpio-controller;
				#gpio-cells = <0x2>;
				interrupt-controller;
				#interrupt-cells = <0x2>;
				linux,phandle = <0x97>;
				phandle = <0x97>;
			};

			sd0-clk {
				samsung,pins = "gpr0-0";
				samsung,pin-function = <0x2>;
				samsung,pin-pud = <0x0>;
				samsung,pin-drv = <0x3>;
				linux,phandle = <0x6b>;
				phandle = <0x6b>;
			};

			sd0-cmd {
				samsung,pins = "gpr0-1";
				samsung,pin-function = <0x2>;
				samsung,pin-pud = <0x0>;
				samsung,pin-drv = <0x3>;
				linux,phandle = <0x6c>;
				phandle = <0x6c>;
			};

			sd0-rdqs {
				samsung,pins = "gpr0-2";
				samsung,pin-function = <0x2>;
				samsung,pin-pud = <0x1>;
				samsung,pin-drv = <0x3>;
				linux,phandle = <0x71>;
				phandle = <0x71>;
			};

			sd0-qrdy {
				samsung,pins = "gpr0-3";
				samsung,pin-function = <0x2>;
				samsung,pin-pud = <0x1>;
				samsung,pin-drv = <0x3>;
				linux,phandle = <0x6d>;
				phandle = <0x6d>;
			};

			sd0-bus-width1 {
				samsung,pins = "gpr1-0";
				samsung,pin-function = <0x2>;
				samsung,pin-pud = <0x3>;
				samsung,pin-drv = <0x3>;
				linux,phandle = <0x6e>;
				phandle = <0x6e>;
			};

			sd0-bus-width4 {
				samsung,pins = "gpr1-1", "gpr1-2", "gpr1-3";
				samsung,pin-function = <0x2>;
				samsung,pin-pud = <0x3>;
				samsung,pin-drv = <0x3>;
				linux,phandle = <0x6f>;
				phandle = <0x6f>;
			};

			sd0-bus-width8 {
				samsung,pins = "gpr1-4", "gpr1-5", "gpr1-6", "gpr1-7";
				samsung,pin-function = <0x2>;
				samsung,pin-pud = <0x3>;
				samsung,pin-drv = <0x3>;
				linux,phandle = <0x70>;
				phandle = <0x70>;
			};

			sd1-clk {
				samsung,pins = "gpr2-0";
				samsung,pin-function = <0x2>;
				samsung,pin-pud = <0x0>;
				samsung,pin-drv = <0x3>;
				linux,phandle = <0xc5>;
				phandle = <0xc5>;
			};

			sd1-cmd {
				samsung,pins = "gpr2-1";
				samsung,pin-function = <0x2>;
				samsung,pin-pud = <0x0>;
				samsung,pin-drv = <0x3>;
				linux,phandle = <0xc6>;
				phandle = <0xc6>;
			};

			sd1-bus-width1 {
				samsung,pins = "gpr3-0";
				samsung,pin-function = <0x2>;
				samsung,pin-pud = <0x3>;
				samsung,pin-drv = <0x3>;
				linux,phandle = <0xc7>;
				phandle = <0xc7>;
			};

			sd1-bus-width4 {
				samsung,pins = "gpr3-1", "gpr3-2", "gpr3-3";
				samsung,pin-function = <0x2>;
				samsung,pin-pud = <0x3>;
				samsung,pin-drv = <0x3>;
				linux,phandle = <0xc8>;
				phandle = <0xc8>;
			};

			sd1-bus-width8 {
				samsung,pins = "gpr3-4", "gpr3-5", "gpr3-6", "gpr3-7";
				samsung,pin-function = <0x2>;
				samsung,pin-pud = <0x3>;
				samsung,pin-drv = <0x3>;
				linux,phandle = <0xc9>;
				phandle = <0xc9>;
			};

			pcie_bus {
				samsung,pins = "gpr3-4", "gpr3-5", "gpr3-6", "gpr3-7";
				samsung,pin-function = <0x3>;
				samsung,pin-pud = <0x3>;
				linux,phandle = <0xca>;
				phandle = <0xca>;
			};

			sd2-clk {
				samsung,pins = "gpr4-0";
				samsung,pin-function = <0x2>;
				samsung,pin-pud = <0x0>;
				samsung,pin-drv = <0x3>;
				linux,phandle = <0x73>;
				phandle = <0x73>;
			};

			sd2-cmd {
				samsung,pins = "gpr4-1";
				samsung,pin-function = <0x2>;
				samsung,pin-pud = <0x0>;
				samsung,pin-drv = <0x3>;
				linux,phandle = <0x74>;
				phandle = <0x74>;
			};

			sd2-cd {
				samsung,pins = "gpr4-2";
				samsung,pin-function = <0x2>;
				samsung,pin-pud = <0x3>;
				samsung,pin-drv = <0x3>;
				linux,phandle = <0xcb>;
				phandle = <0xcb>;
			};

			sd2-bus-width1 {
				samsung,pins = "gpr4-3";
				samsung,pin-function = <0x2>;
				samsung,pin-pud = <0x3>;
				samsung,pin-drv = <0x3>;
				linux,phandle = <0x75>;
				phandle = <0x75>;
			};

			sd2-bus-width4 {
				samsung,pins = "gpr4-4", "gpr4-5", "gpr4-6";
				samsung,pin-function = <0x2>;
				samsung,pin-pud = <0x3>;
				samsung,pin-drv = <0x3>;
				linux,phandle = <0x76>;
				phandle = <0x76>;
			};

			sd2-clk-output {
				samsung,pins = "gpr4-0";
				samsung,pin-function = <0x1>;
				samsung,pin-pud = <0x0>;
				samsung,pin-drv = <0x2>;
				linux,phandle = <0xcc>;
				phandle = <0xcc>;
			};

			sd2-cmd-output {
				samsung,pins = "gpr4-1";
				samsung,pin-function = <0x1>;
				samsung,pin-pud = <0x0>;
				samsung,pin-drv = <0x2>;
				linux,phandle = <0xcd>;
				phandle = <0xcd>;
			};

			initial-state {
				linux,phandle = <0x18>;
				phandle = <0x18>;

				gpr3-0 {
					samsung,pins = "gpr3-0";
					samsung,pin-function = <0x0>;
					samsung,pin-pud = <0x0>;
					samsung,pin-drv = <0x0>;
				};

				gpr3-1 {
					samsung,pins = "gpr3-1";
					samsung,pin-function = <0x0>;
					samsung,pin-pud = <0x1>;
					samsung,pin-drv = <0x0>;
				};

				gpr3-2 {
					samsung,pins = "gpr3-2";
					samsung,pin-function = <0x0>;
					samsung,pin-pud = <0x1>;
					samsung,pin-drv = <0x0>;
				};

				gpr3-3 {
					samsung,pins = "gpr3-3";
					samsung,pin-function = <0x0>;
					samsung,pin-pud = <0x1>;
					samsung,pin-drv = <0x0>;
				};

				gpr3-7 {
					samsung,pins = "gpr3-7";
					samsung,pin-function = <0x0>;
					samsung,pin-pud = <0x0>;
					samsung,pin-drv = <0x0>;
				};
			};
		};

		pinctrl@11090000 {
			compatible = "samsung,exynos5433-pinctrl";
			reg = <0x11090000 0x1000>;
			interrupts = <0x0 0x145 0x4>;
			pinctrl-names = "default";
			pinctrl-0 = <0x19>;
			linux,phandle = <0xce>;
			phandle = <0xce>;

			gpf0 {
				gpio-controller;
				#gpio-cells = <0x2>;
				interrupt-controller;
				#interrupt-cells = <0x2>;
				linux,phandle = <0x47>;
				phandle = <0x47>;
			};

			initial-state {
				linux,phandle = <0x19>;
				phandle = <0x19>;

				gpf0-0 {
					samsung,pins = "gpf0-0";
					samsung,pin-function = <0x0>;
					samsung,pin-pud = <0x3>;
					samsung,pin-drv = <0x0>;
				};

				gpf0-1 {
					samsung,pins = "gpf0-1";
					samsung,pin-function = <0x0>;
					samsung,pin-pud = <0x3>;
					samsung,pin-drv = <0x0>;
				};

				gpf0-2 {
					samsung,pins = "gpf0-2";
					samsung,pin-function = <0x0>;
					samsung,pin-pud = <0x1>;
					samsung,pin-drv = <0x0>;
				};

				gpf0-3 {
					samsung,pins = "gpf0-3";
					samsung,pin-function = <0x0>;
					samsung,pin-pud = <0x3>;
					samsung,pin-drv = <0x0>;
				};

				gpf0-4 {
					samsung,pins = "gpf0-4";
					samsung,pin-function = <0x0>;
					samsung,pin-pud = <0x1>;
					samsung,pin-drv = <0x0>;
				};

				gpf0-5 {
					samsung,pins = "gpf0-5";
					samsung,pin-function = <0x0>;
					samsung,pin-pud = <0x0>;
					samsung,pin-drv = <0x0>;
				};

				gpf0-6 {
					samsung,pins = "gpf0-6";
					samsung,pin-function = <0x0>;
					samsung,pin-pud = <0x1>;
					samsung,pin-drv = <0x0>;
				};

				gpf0-7 {
					samsung,pins = "gpf0-7";
					samsung,pin-function = <0x0>;
					samsung,pin-pud = <0x3>;
					samsung,pin-drv = <0x0>;
				};
			};
		};

		pinctrl@14cd0000 {
			compatible = "samsung,exynos5433-pinctrl";
			reg = <0x14cd0000 0x1000>;
			interrupts = <0x0 0x1b9 0x4>;
			pinctrl-names = "default";
			pinctrl-0 = <0x1a>;
			linux,phandle = <0xcf>;
			phandle = <0xcf>;

			gpj0 {
				gpio-controller;
				#gpio-cells = <0x2>;
				interrupt-controller;
				#interrupt-cells = <0x2>;
				linux,phandle = <0xd0>;
				phandle = <0xd0>;
			};

			hs-i2c4-bus {
				samsung,pins = "gpj0-1", "gpj0-0";
				samsung,pin-function = <0x4>;
				samsung,pin-pud = <0x3>;
				samsung,pin-drv = <0x0>;
				linux,phandle = <0x53>;
				phandle = <0x53>;
			};

			initial-state {
				linux,phandle = <0x1a>;
				phandle = <0x1a>;

				gpj0-2 {
					samsung,pins = "gpj0-2";
					samsung,pin-function = <0x0>;
					samsung,pin-pud = <0x1>;
					samsung,pin-drv = <0x0>;
				};
			};
		};

		pinctrl@14cc0000 {
			compatible = "samsung,exynos5433-pinctrl";
			reg = <0x14cc0000 0x1100>;
			interrupts = <0x0 0x1b8 0x4>;
			pinctrl-names = "default";
			pinctrl-0 = <0x1b>;
			linux,phandle = <0xd1>;
			phandle = <0xd1>;

			gpv7 {
				gpio-controller;
				#gpio-cells = <0x2>;
				interrupt-controller;
				#interrupt-cells = <0x2>;
				linux,phandle = <0x5c>;
				phandle = <0x5c>;
			};

			gpb0 {
				gpio-controller;
				#gpio-cells = <0x2>;
				interrupt-controller;
				#interrupt-cells = <0x2>;
				linux,phandle = <0xd2>;
				phandle = <0xd2>;
			};

			gpc0 {
				gpio-controller;
				#gpio-cells = <0x2>;
				interrupt-controller;
				#interrupt-cells = <0x2>;
				linux,phandle = <0x46>;
				phandle = <0x46>;
			};

			gpc1 {
				gpio-controller;
				#gpio-cells = <0x2>;
				interrupt-controller;
				#interrupt-cells = <0x2>;
				linux,phandle = <0xd3>;
				phandle = <0xd3>;
			};

			gpc2 {
				gpio-controller;
				#gpio-cells = <0x2>;
				interrupt-controller;
				#interrupt-cells = <0x2>;
				linux,phandle = <0xd4>;
				phandle = <0xd4>;
			};

			gpc3 {
				gpio-controller;
				#gpio-cells = <0x2>;
				interrupt-controller;
				#interrupt-cells = <0x2>;
				linux,phandle = <0xd5>;
				phandle = <0xd5>;
			};

			gpg0 {
				gpio-controller;
				#gpio-cells = <0x2>;
				interrupt-controller;
				#interrupt-cells = <0x2>;
				linux,phandle = <0x2d>;
				phandle = <0x2d>;
			};

			gpd0 {
				gpio-controller;
				#gpio-cells = <0x2>;
				interrupt-controller;
				#interrupt-cells = <0x2>;
				linux,phandle = <0x96>;
				phandle = <0x96>;
			};

			gpd1 {
				gpio-controller;
				#gpio-cells = <0x2>;
				interrupt-controller;
				#interrupt-cells = <0x2>;
				linux,phandle = <0xd6>;
				phandle = <0xd6>;
			};

			gpd2 {
				gpio-controller;
				#gpio-cells = <0x2>;
				interrupt-controller;
				#interrupt-cells = <0x2>;
				linux,phandle = <0xd7>;
				phandle = <0xd7>;
			};

			gpd4 {
				gpio-controller;
				#gpio-cells = <0x2>;
				interrupt-controller;
				#interrupt-cells = <0x2>;
				linux,phandle = <0xd8>;
				phandle = <0xd8>;
			};

			gpd8 {
				gpio-controller;
				#gpio-cells = <0x2>;
				interrupt-controller;
				#interrupt-cells = <0x2>;
				linux,phandle = <0xd9>;
				phandle = <0xd9>;
			};

			gpd6 {
				gpio-controller;
				#gpio-cells = <0x2>;
				interrupt-controller;
				#interrupt-cells = <0x2>;
				linux,phandle = <0x43>;
				phandle = <0x43>;
			};

			gpd7 {
				gpio-controller;
				#gpio-cells = <0x2>;
				interrupt-controller;
				#interrupt-cells = <0x2>;
				linux,phandle = <0xda>;
				phandle = <0xda>;
			};

			gpg1 {
				gpio-controller;
				#gpio-cells = <0x2>;
				interrupt-controller;
				#interrupt-cells = <0x2>;
				linux,phandle = <0xdb>;
				phandle = <0xdb>;
			};

			gpg2 {
				gpio-controller;
				#gpio-cells = <0x2>;
				interrupt-controller;
				#interrupt-cells = <0x2>;
				linux,phandle = <0xdc>;
				phandle = <0xdc>;
			};

			gpg3 {
				gpio-controller;
				#gpio-cells = <0x2>;
				interrupt-controller;
				#interrupt-cells = <0x2>;
				linux,phandle = <0xdd>;
				phandle = <0xdd>;
			};

			hs-i2c8-bus {
				samsung,pins = "gpb0-1", "gpb0-0";
				samsung,pin-function = <0x4>;
				samsung,pin-pud = <0x3>;
				samsung,pin-drv = <0x0>;
				linux,phandle = <0x5e>;
				phandle = <0x5e>;
			};

			hs-i2c9-bus {
				samsung,pins = "gpb0-3", "gpb0-2";
				samsung,pin-function = <0x4>;
				samsung,pin-pud = <0x3>;
				samsung,pin-drv = <0x0>;
				linux,phandle = <0x61>;
				phandle = <0x61>;
			};

			i2s1-bus {
				samsung,pins = "gpd4-0", "gpd4-1", "gpd4-2", "gpd4-3", "gpd4-4";
				samsung,pin-function = <0x2>;
				samsung,pin-pud = <0x0>;
				samsung,pin-drv = <0x0>;
				linux,phandle = <0xde>;
				phandle = <0xde>;
			};

			pcm1-bus {
				samsung,pins = "gpd4-0", "gpd4-1", "gpd4-2", "gpd4-3", "gpd4-4";
				samsung,pin-function = <0x3>;
				samsung,pin-pud = <0x0>;
				samsung,pin-drv = <0x0>;
				linux,phandle = <0xdf>;
				phandle = <0xdf>;
			};

			spdif-bus {
				samsung,pins = "gpd4-3", "gpd4-4";
				samsung,pin-function = <0x4>;
				samsung,pin-pud = <0x0>;
				samsung,pin-drv = <0x0>;
				linux,phandle = <0xe0>;
				phandle = <0xe0>;
			};

			fimc-is-spi-pin0 {
				samsung,pins = "gpc3-3", "gpc3-2", "gpc3-1", "gpc3-0";
				samsung,pin-function = <0x2>;
				samsung,pin-pud = <0x0>;
				samsung,pin-drv = <0x0>;
				linux,phandle = <0xe1>;
				phandle = <0xe1>;
			};

			fimc-is-spi-pin1 {
				samsung,pins = "gpc3-7", "gpc3-6", "gpc3-5", "gpc3-4";
				samsung,pin-function = <0x2>;
				samsung,pin-pud = <0x0>;
				samsung,pin-drv = <0x0>;
				linux,phandle = <0xe2>;
				phandle = <0xe2>;
			};

			uart0-bus {
				samsung,pins = "gpd0-3", "gpd0-2", "gpd0-1", "gpd0-0";
				samsung,pin-function = <0x2>;
				samsung,pin-pud = <0x0>;
				linux,phandle = <0x3d>;
				phandle = <0x3d>;
			};

			hs-i2c2-bus {
				samsung,pins = "gpd0-3", "gpd0-2";
				samsung,pin-function = <0x3>;
				samsung,pin-pud = <0x3>;
				samsung,pin-drv = <0x0>;
				linux,phandle = <0x51>;
				phandle = <0x51>;
			};

			uart2-bus {
				samsung,pins = "gpd1-5", "gpd1-4";
				samsung,pin-function = <0x2>;
				samsung,pin-pud = <0x0>;
				linux,phandle = <0x3f>;
				phandle = <0x3f>;
			};

			uart1-bus {
				samsung,pins = "gpd1-3", "gpd1-2", "gpd1-1", "gpd1-0";
				samsung,pin-function = <0x2>;
				samsung,pin-pud = <0x0>;
				linux,phandle = <0x3e>;
				phandle = <0x3e>;
			};

			hs-i2c3-bus {
				samsung,pins = "gpd1-3", "gpd1-2";
				samsung,pin-function = <0x3>;
				samsung,pin-pud = <0x3>;
				samsung,pin-drv = <0x0>;
				linux,phandle = <0x52>;
				phandle = <0x52>;
			};

			hs-i2c0-bus {
				samsung,pins = "gpd2-1", "gpd2-0";
				samsung,pin-function = <0x2>;
				samsung,pin-pud = <0x3>;
				samsung,pin-drv = <0x0>;
				linux,phandle = <0x4f>;
				phandle = <0x4f>;
			};

			hs-i2c1-bus {
				samsung,pins = "gpd2-3", "gpd2-2";
				samsung,pin-function = <0x2>;
				samsung,pin-pud = <0x3>;
				samsung,pin-drv = <0x0>;
				linux,phandle = <0x50>;
				phandle = <0x50>;
			};

			pwm0-out {
				samsung,pins = "gpd2-4";
				samsung,pin-function = <0x2>;
				samsung,pin-pud = <0x0>;
				samsung,pin-drv = <0x0>;
				linux,phandle = <0x4e>;
				phandle = <0x4e>;
			};

			pwm1-out {
				samsung,pins = "gpd2-5";
				samsung,pin-function = <0x2>;
				samsung,pin-pud = <0x0>;
				samsung,pin-drv = <0x0>;
				linux,phandle = <0xe3>;
				phandle = <0xe3>;
			};

			pwm2-out {
				samsung,pins = "gpd2-6";
				samsung,pin-function = <0x2>;
				samsung,pin-pud = <0x0>;
				samsung,pin-drv = <0x0>;
				linux,phandle = <0xe4>;
				phandle = <0xe4>;
			};

			pwm3-out {
				samsung,pins = "gpd2-7";
				samsung,pin-function = <0x2>;
				samsung,pin-pud = <0x0>;
				samsung,pin-drv = <0x0>;
				linux,phandle = <0xe5>;
				phandle = <0xe5>;
			};

			spi1-bus {
				samsung,pins = "gpd6-2", "gpd6-4", "gpd6-5";
				samsung,pin-function = <0x2>;
				samsung,pin-pud = <0x3>;
				samsung,pin-drv = <0x0>;
				linux,phandle = <0x42>;
				phandle = <0x42>;
			};

			hs-i2c7-bus {
				samsung,pins = "gpd2-7", "gpd2-6";
				samsung,pin-function = <0x4>;
				samsung,pin-pud = <0x3>;
				samsung,pin-drv = <0x0>;
				linux,phandle = <0x59>;
				phandle = <0x59>;
			};

			spi0-bus {
				samsung,pins = "gpd8-0", "gpd6-0", "gpd6-1";
				samsung,pin-function = <0x2>;
				samsung,pin-pud = <0x3>;
				samsung,pin-drv = <0x0>;
				linux,phandle = <0x41>;
				phandle = <0x41>;
			};

			hs-i2c10-bus {
				samsung,pins = "gpg3-1", "gpg3-0";
				samsung,pin-function = <0x4>;
				samsung,pin-pud = <0x3>;
				samsung,pin-drv = <0x0>;
				linux,phandle = <0x64>;
				phandle = <0x64>;
			};

			hs-i2c11-bus {
				samsung,pins = "gpg3-3", "gpg3-2";
				samsung,pin-function = <0x4>;
				samsung,pin-pud = <0x3>;
				samsung,pin-drv = <0x0>;
				linux,phandle = <0x65>;
				phandle = <0x65>;
			};

			spi3-bus {
				samsung,pins = "gpg3-4", "gpg3-6", "gpg3-7";
				samsung,pin-function = <0x3>;
				samsung,pin-pud = <0x3>;
				samsung,pin-drv = <0x0>;
				linux,phandle = <0x4a>;
				phandle = <0x4a>;
			};

			spi4-bus {
				samsung,pins = "gpv7-1", "gpv7-3", "gpv7-4";
				samsung,pin-function = <0x3>;
				samsung,pin-pud = <0x3>;
				samsung,pin-drv = <0x0>;
				linux,phandle = <0x4c>;
				phandle = <0x4c>;
			};

			fimc-is-uart {
				samsung,pins = "gpc1-1", "gpc0-7";
				samsung,pin-function = <0x3>;
				samsung,pin-pud = <0x0>;
				samsung,pin-drv = <0x0>;
				linux,phandle = <0xe6>;
				phandle = <0xe6>;
			};

			fimc-is-ch0_i2c {
				samsung,pins = "gpc2-1", "gpc2-0";
				samsung,pin-function = <0x2>;
				samsung,pin-pud = <0x0>;
				samsung,pin-drv = <0x0>;
				linux,phandle = <0xe7>;
				phandle = <0xe7>;
			};

			fimc-is-ch0_mclk {
				samsung,pins = "gpd7-0";
				samsung,pin-function = <0x2>;
				samsung,pin-pud = <0x0>;
				samsung,pin-drv = <0x0>;
				linux,phandle = <0xe8>;
				phandle = <0xe8>;
			};

			fimc-is-ch1-i2c {
				samsung,pins = "gpc2-3", "gpc2-2";
				samsung,pin-function = <0x2>;
				samsung,pin-pud = <0x0>;
				samsung,pin-drv = <0x0>;
				linux,phandle = <0xe9>;
				phandle = <0xe9>;
			};

			fimc-is-ch1-mclk {
				samsung,pins = "gpd7-1";
				samsung,pin-function = <0x2>;
				samsung,pin-pud = <0x0>;
				samsung,pin-drv = <0x0>;
				linux,phandle = <0xea>;
				phandle = <0xea>;
			};

			fimc-is-ch2-i2c {
				samsung,pins = "gpc2-5", "gpc2-4";
				samsung,pin-function = <0x2>;
				samsung,pin-pud = <0x0>;
				samsung,pin-drv = <0x0>;
				linux,phandle = <0xeb>;
				phandle = <0xeb>;
			};

			fimc-is-ch2-mclk {
				samsung,pins = "gpd7-2";
				samsung,pin-function = <0x2>;
				samsung,pin-pud = <0x0>;
				samsung,pin-drv = <0x0>;
				linux,phandle = <0xec>;
				phandle = <0xec>;
			};

			initial-state {
				linux,phandle = <0x1b>;
				phandle = <0x1b>;

				gpv7-0 {
					samsung,pins = "gpv7-0";
					samsung,pin-function = <0x0>;
					samsung,pin-pud = <0x1>;
					samsung,pin-drv = <0x0>;
				};

				gpv7-1 {
					samsung,pins = "gpv7-1";
					samsung,pin-function = <0x0>;
					samsung,pin-pud = <0x1>;
					samsung,pin-drv = <0x0>;
				};

				gpv7-2 {
					samsung,pins = "gpv7-2";
					samsung,pin-function = <0x0>;
					samsung,pin-pud = <0x0>;
					samsung,pin-drv = <0x0>;
				};

				gpv7-3 {
					samsung,pins = "gpv7-3";
					samsung,pin-function = <0x0>;
					samsung,pin-pud = <0x1>;
					samsung,pin-drv = <0x0>;
				};

				gpv7-4 {
					samsung,pins = "gpv7-4";
					samsung,pin-function = <0x0>;
					samsung,pin-pud = <0x1>;
					samsung,pin-drv = <0x0>;
				};

				gpv7-5 {
					samsung,pins = "gpv7-5";
					samsung,pin-function = <0x0>;
					samsung,pin-pud = <0x1>;
					samsung,pin-drv = <0x0>;
				};

				gpb0-4 {
					samsung,pins = "gpb0-4";
					samsung,pin-function = <0x0>;
					samsung,pin-pud = <0x1>;
					samsung,pin-drv = <0x0>;
				};

				gpc0-2 {
					samsung,pins = "gpc0-2";
					samsung,pin-function = <0x0>;
					samsung,pin-pud = <0x1>;
					samsung,pin-drv = <0x0>;
				};

				gpc0-5 {
					samsung,pins = "gpc0-5";
					samsung,pin-function = <0x0>;
					samsung,pin-pud = <0x1>;
					samsung,pin-drv = <0x0>;
				};

				gpc0-7 {
					samsung,pins = "gpc0-7";
					samsung,pin-function = <0x0>;
					samsung,pin-pud = <0x1>;
					samsung,pin-drv = <0x0>;
				};

				gpc1-1 {
					samsung,pins = "gpc1-1";
					samsung,pin-function = <0x0>;
					samsung,pin-pud = <0x1>;
					samsung,pin-drv = <0x0>;
				};

				gpc3-4 {
					samsung,pins = "gpc3-4";
					samsung,pin-function = <0x0>;
					samsung,pin-pud = <0x0>;
					samsung,pin-drv = <0x0>;
				};

				gpc3-5 {
					samsung,pins = "gpc3-5";
					samsung,pin-function = <0x0>;
					samsung,pin-pud = <0x0>;
					samsung,pin-drv = <0x0>;
				};

				gpc3-6 {
					samsung,pins = "gpc3-6";
					samsung,pin-function = <0x0>;
					samsung,pin-pud = <0x0>;
					samsung,pin-drv = <0x0>;
				};

				gpc3-7 {
					samsung,pins = "gpc3-7";
					samsung,pin-function = <0x0>;
					samsung,pin-pud = <0x0>;
					samsung,pin-drv = <0x0>;
				};

				gpg0-0 {
					samsung,pins = "gpg0-0";
					samsung,pin-function = <0x1>;
					samsung,pin-pud = <0x0>;
					samsung,pin-drv = <0x0>;
				};

				gpg0-1 {
					samsung,pins = "gpg0-1";
					samsung,pin-function = <0x2>;
					samsung,pin-pud = <0x1>;
					samsung,pin-drv = <0x0>;
				};

				gpd2-5 {
					samsung,pins = "gpd2-5";
					samsung,pin-function = <0x0>;
					samsung,pin-pud = <0x1>;
					samsung,pin-drv = <0x0>;
				};

				gpd4-0 {
					samsung,pins = "gpd4-0";
					samsung,pin-function = <0x0>;
					samsung,pin-pud = <0x0>;
					samsung,pin-drv = <0x0>;
				};

				gpd4-1 {
					samsung,pins = "gpd4-1";
					samsung,pin-function = <0x0>;
					samsung,pin-pud = <0x1>;
					samsung,pin-drv = <0x0>;
				};

				gpd4-2 {
					samsung,pins = "gpd4-2";
					samsung,pin-function = <0x0>;
					samsung,pin-pud = <0x1>;
					samsung,pin-drv = <0x0>;
				};

				gpd4-3 {
					samsung,pins = "gpd4-3";
					samsung,pin-function = <0x0>;
					samsung,pin-pud = <0x1>;
					samsung,pin-drv = <0x0>;
				};

				gpd4-4 {
					samsung,pins = "gpd4-4";
					samsung,pin-function = <0x0>;
					samsung,pin-pud = <0x1>;
					samsung,pin-drv = <0x0>;
				};

				gpd6-3 {
					samsung,pins = "gpd6-3";
					samsung,pin-function = <0x0>;
					samsung,pin-pud = <0x1>;
					samsung,pin-drv = <0x0>;
				};

				gpd8-1 {
					samsung,pins = "gpd8-1";
					samsung,pin-function = <0x0>;
					samsung,pin-pud = <0x3>;
					samsung,pin-drv = <0x0>;
				};

				gpg1-0 {
					samsung,pins = "gpg1-0";
					samsung,pin-function = <0x0>;
					samsung,pin-pud = <0x1>;
					samsung,pin-drv = <0x0>;
				};

				gpg1-1 {
					samsung,pins = "gpg1-1";
					samsung,pin-function = <0x0>;
					samsung,pin-pud = <0x1>;
					samsung,pin-drv = <0x0>;
				};

				gpg1-2 {
					samsung,pins = "gpg1-2";
					samsung,pin-function = <0x0>;
					samsung,pin-pud = <0x1>;
					samsung,pin-drv = <0x0>;
				};

				gpg1-3 {
					samsung,pins = "gpg1-3";
					samsung,pin-function = <0x0>;
					samsung,pin-pud = <0x1>;
					samsung,pin-drv = <0x0>;
				};

				gpg1-4 {
					samsung,pins = "gpg1-4";
					samsung,pin-function = <0x0>;
					samsung,pin-pud = <0x1>;
					samsung,pin-drv = <0x0>;
				};

				gpg2-0 {
					samsung,pins = "gpg2-0";
					samsung,pin-function = <0x0>;
					samsung,pin-pud = <0x1>;
					samsung,pin-drv = <0x0>;
				};

				gpg2-1 {
					samsung,pins = "gpg2-1";
					samsung,pin-function = <0x0>;
					samsung,pin-pud = <0x1>;
					samsung,pin-drv = <0x0>;
				};

				gpg3-0 {
					samsung,pins = "gpg3-0";
					samsung,pin-function = <0x0>;
					samsung,pin-pud = <0x1>;
					samsung,pin-drv = <0x0>;
				};

				gpg3-1 {
					samsung,pins = "gpg3-1";
					samsung,pin-function = <0x0>;
					samsung,pin-pud = <0x1>;
					samsung,pin-drv = <0x0>;
				};

				gpg3-5 {
					samsung,pins = "gpg3-5";
					samsung,pin-function = <0x0>;
					samsung,pin-pud = <0x1>;
					samsung,pin-drv = <0x0>;
				};
			};
		};

		pinctrl@14ce0000 {
			compatible = "samsung,exynos5433-pinctrl";
			reg = <0x14ce0000 0x1100>;
			interrupts = <0x0 0x1ba 0x4>;
			pinctrl-names = "default";
			pinctrl-0 = <0x1c>;
			linux,phandle = <0xed>;
			phandle = <0xed>;

			gpj1 {
				gpio-controller;
				#gpio-cells = <0x2>;
				interrupt-controller;
				#interrupt-cells = <0x2>;
				linux,phandle = <0xee>;
				phandle = <0xee>;
			};

			hs-i2c5-bus {
				samsung,pins = "gpj1-1", "gpj1-0";
				samsung,pin-function = <0x4>;
				samsung,pin-pud = <0x3>;
				samsung,pin-drv = <0x0>;
				linux,phandle = <0x54>;
				phandle = <0x54>;
			};

			initial-state {
				linux,phandle = <0x1c>;
				phandle = <0x1c>;

				gpj1-2 {
					samsung,pins = "gpj1-2";
					samsung,pin-function = <0x0>;
					samsung,pin-pud = <0x1>;
					samsung,pin-drv = <0x0>;
				};
			};
		};

		system-controller@105c0000 {
			compatible = "samsung,exynos5433-pmu", "syscon";
			reg = <0x105c0000 0x5008>;
			#clock-cells = <0x1>;
			clock-names = "clkout16";
			clocks = <0x9>;
			assigned-clocks = <0x8 0x0>;
			assigned-clock-parents = <0x9>;
			linux,phandle = <0x8>;
			phandle = <0x8>;
		};

		interrupt-controller@11001000 {
			compatible = "arm,gic-400";
			#interrupt-cells = <0x3>;
			interrupt-controller;
			reg = <0x11001000 0x1000 0x11002000 0x2000 0x11004000 0x2000 0x11006000 0x2000>;
			interrupts = <0x1 0x9 0xf04>;
			linux,phandle = <0x1>;
			phandle = <0x1>;
		};

		video-phy {
			compatible = "samsung,exynos5433-mipi-video-phy";
			#phy-cells = <0x1>;
			samsung,pmu-syscon = <0x8>;
			samsung,cam0-sysreg = <0x1d>;
			samsung,cam1-sysreg = <0x1e>;
			samsung,disp-sysreg = <0x1f>;
			linux,phandle = <0x26>;
			phandle = <0x26>;
		};

		decon@13800000 {
			compatible = "samsung,exynos5433-decon";
			reg = <0x13800000 0x2104>;
			clocks = <0xe 0x71 0xe 0x29 0xe 0x2d 0xe 0x3e 0xe 0x46 0xe 0x6b 0xe 0x6c>;
			clock-names = "pclk", "aclk_decon", "aclk_smmu_decon0x", "aclk_xiu_decon0x", "pclk_smmu_decon0x", "sclk_decon_vclk", "sclk_decon_eclk";
			interrupt-names = "fifo", "vsync", "lcd_sys";
			interrupts = <0x0 0xc9 0x4 0x0 0xca 0x4 0x0 0xcb 0x4>;
			samsung,disp-sysreg = <0x1f>;
			status = "okay";
			iommus = <0x20 0x21>;
			iommu-names = "m0", "m1";
			linux,phandle = <0xef>;
			phandle = <0xef>;

			ports {
				#address-cells = <0x1>;
				#size-cells = <0x0>;

				port@0 {
					reg = <0x0>;

					endpoint {
						remote-endpoint = <0x22>;
						linux,phandle = <0x2f>;
						phandle = <0x2f>;
					};
				};
			};
		};

		decon@13880000 {
			compatible = "samsung,exynos5433-decon-tv";
			reg = <0x13880000 0x20b8>;
			clocks = <0xe 0x58 0xe 0x28 0xe 0x2b 0xe 0x3c 0xe 0x44 0xe 0x5e 0xe 0x6a>;
			clock-names = "pclk", "aclk_decon", "aclk_smmu_decon0x", "aclk_xiu_decon0x", "pclk_smmu_decon0x", "sclk_decon_vclk", "sclk_decon_eclk";
			samsung,disp-sysreg = <0x1f>;
			interrupt-names = "fifo", "vsync", "lcd_sys";
			interrupts = <0x0 0xd2 0x4 0x0 0xd3 0x4 0x0 0xd4 0x4>;
			status = "okay";
			iommus = <0x23 0x24>;
			iommu-names = "m0", "m1";
			linux,phandle = <0xf0>;
			phandle = <0xf0>;

			ports {
				#address-cells = <0x1>;
				#size-cells = <0x0>;

				port@0 {
					reg = <0x0>;

					endpoint {
						remote-endpoint = <0x25>;
						linux,phandle = <0x34>;
						phandle = <0x34>;
					};
				};
			};
		};

		dsi@13900000 {
			compatible = "samsung,exynos5433-mipi-dsi";
			reg = <0x13900000 0xc0>;
			interrupts = <0x0 0xcd 0x4>;
			phys = <0x26 0x1>;
			phy-names = "dsim";
			clocks = <0xe 0x57 0xe 0x5f 0xe 0x60 0xe 0x65 0xe 0x69>;
			clock-names = "bus_clk", "phyclk_mipidphy0_bitclkdiv8", "phyclk_mipidphy0_rxclkesc0", "sclk_rgb_vclk_to_dsim0", "sclk_mipi";
			status = "okay";
			#address-cells = <0x1>;
			#size-cells = <0x0>;
			vddcore-supply = <0x27>;
			vddio-supply = <0x28>;
			samsung,burst-clock-frequency = <0x1e848000>;
			samsung,esc-clock-frequency = <0xf42400>;
			samsung,pll-clock-frequency = <0x16e3600>;
			pinctrl-names = "default";
			pinctrl-0 = <0x29>;
			linux,phandle = <0xf1>;
			phandle = <0xf1>;

			ports {
				#address-cells = <0x1>;
				#size-cells = <0x0>;

				port@0 {
					reg = <0x0>;

					endpoint {
						remote-endpoint = <0x2a>;
						linux,phandle = <0x30>;
						phandle = <0x30>;
					};
				};
			};

			panel@0 {
				compatible = "samsung,s6e3ha2";
				reg = <0x0>;
				vdd3-supply = <0x2b>;
				vci-supply = <0x2c>;
				reset-gpios = <0x2d 0x0 0x1>;
				enable-gpios = <0x2e 0x5 0x0>;
			};
		};

		mic@13930000 {
			compatible = "samsung,exynos5433-mic";
			reg = <0x13930000 0x48>;
			clocks = <0xe 0x55 0xe 0x66>;
			clock-names = "pclk_mic0", "sclk_rgb_vclk_to_mic0";
			samsung,disp-syscon = <0x1f>;
			status = "okay";
			linux,phandle = <0xf2>;
			phandle = <0xf2>;

			ports {
				#address-cells = <0x1>;
				#size-cells = <0x0>;

				port@0 {
					reg = <0x0>;

					endpoint {
						remote-endpoint = <0x2f>;
						linux,phandle = <0x22>;
						phandle = <0x22>;
					};
				};

				port@1 {
					reg = <0x1>;

					endpoint {
						remote-endpoint = <0x30>;
						linux,phandle = <0x2a>;
						phandle = <0x2a>;
					};
				};
			};
		};

		hdmi@13970000 {
			compatible = "samsung,exynos5433-hdmi";
			reg = <0x13970000 0x70000>;
			interrupts = <0x0 0xd0 0x4>;
			clocks = <0xe 0x54 0xe 0x53 0xe 0x61 0xe 0x62 0xe 0x70 0xe 0xf 0xe 0x6f 0xe 0x10 0x9 0xe 0x68>;
			clock-names = "hdmi_pclk", "hdmi_i_pclk", "i_tmds_clk", "i_pixel_clk", "tmds_clko", "tmds_clko_user", "pixel_clko", "pixel_clko_user", "oscclk", "i_spdif_clk";
			phy = <0x31>;
			ddc = <0x32>;
			samsung,syscon-phandle = <0x8>;
			samsung,sysreg-phandle = <0x1f>;
			status = "okay";
			hpd-gpios = <0x33 0x0 0x0>;
			vdd-supply = <0x27>;
			vdd_osc-supply = <0x28>;
			vdd_pll-supply = <0x27>;
			linux,phandle = <0xf3>;
			phandle = <0xf3>;

			ports {
				#address-cells = <0x1>;
				#size-cells = <0x0>;

				port@0 {
					reg = <0x0>;

					endpoint {
						remote-endpoint = <0x34>;
						linux,phandle = <0x25>;
						phandle = <0x25>;
					};
				};

				port@1 {
					reg = <0x1>;

					endpoint {
						remote-endpoint = <0x35>;
						linux,phandle = <0x5d>;
						phandle = <0x5d>;
					};
				};
			};
		};

		hdmiphy@13af0000 {
			reg = <0x13af0000 0x80>;
			linux,phandle = <0x31>;
			phandle = <0x31>;
		};

		syscon@13b80000 {
			compatible = "syscon";
			reg = <0x13b80000 0x1010>;
			linux,phandle = <0x1f>;
			phandle = <0x1f>;
		};

		syscon@120f0000 {
			compatible = "syscon";
			reg = <0x120f0000 0x1020>;
			linux,phandle = <0x1d>;
			phandle = <0x1d>;
		};

		syscon@145f0000 {
			compatible = "syscon";
			reg = <0x145f0000 0x1038>;
			linux,phandle = <0x1e>;
			phandle = <0x1e>;
		};

		video-scaler@13C00000 {
			compatible = "samsung,exynos5433-gsc";
			reg = <0x13c00000 0x1000>;
			interrupts = <0x0 0x129 0x4>;
			clock-names = "pclk", "aclk", "aclk_xiu", "aclk_gsclbend";
			clocks = <0x10 0x19 0x10 0xe 0x10 0x7 0x10 0xa>;
			iommus = <0x36>;
			linux,phandle = <0xf4>;
			phandle = <0xf4>;
		};

		video-scaler@13C10000 {
			compatible = "samsung,exynos5433-gsc";
			reg = <0x13c10000 0x1000>;
			interrupts = <0x0 0x12a 0x4>;
			clock-names = "pclk", "aclk", "aclk_xiu", "aclk_gsclbend";
			clocks = <0x10 0x18 0x10 0xd 0x10 0x7 0x10 0xa>;
			iommus = <0x37>;
			linux,phandle = <0xf5>;
			phandle = <0xf5>;
		};

		video-scaler@13C20000 {
			compatible = "samsung,exynos5433-gsc";
			reg = <0x13c20000 0x1000>;
			interrupts = <0x0 0x12b 0x4>;
			clock-names = "pclk", "aclk", "aclk_xiu", "aclk_gsclbend";
			clocks = <0x10 0x17 0x10 0xc 0x10 0x7 0x10 0xa>;
			iommus = <0x38>;
			linux,phandle = <0xf6>;
			phandle = <0xf6>;
		};

		codec@15020000 {
			compatible = "samsung,exynos5433-jpeg";
			reg = <0x15020000 0x10000>;
			interrupts = <0x0 0x19b 0x4>;
			clock-names = "pclk", "aclk", "aclk_xiu", "sclk";
			clocks = <0x11 0x17 0x11 0xc 0x11 0x9 0x11 0x1d>;
			iommus = <0x39>;
			linux,phandle = <0xf7>;
			phandle = <0xf7>;
		};

		codec@152E0000 {
			compatible = "samsung,exynos5433-mfc";
			reg = <0x152e0000 0x10000>;
			interrupts = <0x0 0x166 0x4>;
			clock-names = "pclk", "aclk", "aclk_xiu";
			clocks = <0x12 0x10 0x12 0x9 0x12 0x6>;
			iommus = <0x3a 0x3b>;
			iommu-names = "left", "right";
			linux,phandle = <0xf8>;
			phandle = <0xf8>;
		};

		sysmmu@13a00000 {
			compatible = "samsung,exynos-sysmmu";
			reg = <0x13a00000 0x1000>;
			interrupts = <0x0 0xc0 0x4>;
			clock-names = "pclk", "aclk";
			clocks = <0xe 0x46 0xe 0x2d>;
			#iommu-cells = <0x0>;
			linux,phandle = <0x20>;
			phandle = <0x20>;
		};

		sysmmu@13a10000 {
			compatible = "samsung,exynos-sysmmu";
			reg = <0x13a10000 0x1000>;
			interrupts = <0x0 0xc2 0x4>;
			clock-names = "pclk", "aclk";
			clocks = <0xe 0x45 0xe 0x2c>;
			#iommu-cells = <0x0>;
			linux,phandle = <0x21>;
			phandle = <0x21>;
		};

		sysmmu@13a20000 {
			compatible = "samsung,exynos-sysmmu";
			reg = <0x13a20000 0x1000>;
			interrupts = <0x0 0xd6 0x4>;
			clock-names = "pclk", "aclk";
			clocks = <0xe 0x44 0xe 0x2b>;
			#iommu-cells = <0x0>;
			linux,phandle = <0x23>;
			phandle = <0x23>;
		};

		sysmmu@13a30000 {
			compatible = "samsung,exynos-sysmmu";
			reg = <0x13a30000 0x1000>;
			interrupts = <0x0 0xd8 0x4>;
			clock-names = "pclk", "aclk";
			clocks = <0xe 0x43 0xe 0x2a>;
			#iommu-cells = <0x0>;
			linux,phandle = <0x24>;
			phandle = <0x24>;
		};

		sysmmu@13c80000 {
			compatible = "samsung,exynos-sysmmu";
			reg = <0x13c80000 0x1000>;
			interrupts = <0x0 0x120 0x4>;
			clock-names = "aclk", "pclk";
			clocks = <0x10 0xf 0x10 0x1a>;
			#iommu-cells = <0x0>;
			linux,phandle = <0x36>;
			phandle = <0x36>;
		};

		sysmmu@13c90000 {
			compatible = "samsung,exynos-sysmmu";
			reg = <0x13c90000 0x1000>;
			interrupts = <0x0 0x122 0x4>;
			clock-names = "aclk", "pclk";
			clocks = <0x10 0x10 0x10 0x1b>;
			#iommu-cells = <0x0>;
			linux,phandle = <0x37>;
			phandle = <0x37>;
		};

		sysmmu@13ca0000 {
			compatible = "samsung,exynos-sysmmu";
			reg = <0x13ca0000 0x1000>;
			interrupts = <0x0 0x124 0x4>;
			clock-names = "aclk", "pclk";
			clocks = <0x10 0x11 0x10 0x1c>;
			#iommu-cells = <0x0>;
			linux,phandle = <0x38>;
			phandle = <0x38>;
		};

		sysmmu@15060000 {
			compatible = "samsung,exynos-sysmmu";
			reg = <0x15060000 0x1000>;
			interrupts = <0x0 0x198 0x4>;
			clock-names = "pclk", "aclk";
			clocks = <0x11 0x1c 0x11 0x11>;
			#iommu-cells = <0x0>;
			linux,phandle = <0x39>;
			phandle = <0x39>;
		};

		sysmmu@15200000 {
			compatible = "samsung,exynos-sysmmu";
			reg = <0x15200000 0x1000>;
			interrupts = <0x0 0x160 0x4>;
			clock-names = "pclk", "aclk";
			clocks = <0x12 0x12 0x12 0xb>;
			#iommu-cells = <0x0>;
			linux,phandle = <0x3a>;
			phandle = <0x3a>;
		};

		sysmmu@15210000 {
			compatible = "samsung,exynos-sysmmu";
			reg = <0x15210000 0x1000>;
			interrupts = <0x0 0x162 0x4>;
			clock-names = "pclk", "aclk";
			clocks = <0x12 0x11 0x12 0xa>;
			#iommu-cells = <0x0>;
			linux,phandle = <0x3b>;
			phandle = <0x3b>;
		};

		serial@14c10000 {
			compatible = "samsung,exynos5433-uart";
			reg = <0x14c10000 0x100>;
			interrupts = <0x0 0x1a5 0x4>;
			clocks = <0x3c 0x6 0x3c 0x24>;
			clock-names = "uart", "clk_uart_baud0";
			pinctrl-names = "default";
			pinctrl-0 = <0x3d>;
			status = "disabled";
			linux,phandle = <0xf9>;
			phandle = <0xf9>;
		};

		serial@14c20000 {
			compatible = "samsung,exynos5433-uart";
			reg = <0x14c20000 0x100>;
			interrupts = <0x0 0x1a6 0x4>;
			clocks = <0x3c 0x5 0x3c 0x23>;
			clock-names = "uart", "clk_uart_baud0";
			pinctrl-names = "default";
			pinctrl-0 = <0x3e>;
			status = "okay";
			linux,phandle = <0xfa>;
			phandle = <0xfa>;
		};

		serial@14c30000 {
			compatible = "samsung,exynos5433-uart";
			reg = <0x14c30000 0x100>;
			interrupts = <0x0 0x1a7 0x4>;
			clocks = <0x3c 0x4 0x3c 0x22>;
			clock-names = "uart", "clk_uart_baud0";
			pinctrl-names = "default";
			pinctrl-0 = <0x3f>;
			status = "disabled";
			linux,phandle = <0xfb>;
			phandle = <0xfb>;
		};

		spi@14d20000 {
			compatible = "samsung,exynos5433-spi";
			reg = <0x14d20000 0x100>;
			interrupts = <0x0 0x1b0 0x4>;
			dmas = <0x40 0x9 0x40 0x8>;
			dma-names = "tx", "rx";
			#address-cells = <0x1>;
			#size-cells = <0x0>;
			clocks = <0x3c 0x3 0x3c 0x21 0x3c 0x3d>;
			clock-names = "spi", "spi_busclk0", "spi_ioclk";
			samsung,spi-src-clk = <0x0>;
			pinctrl-names = "default";
			pinctrl-0 = <0x41>;
			num-cs = <0x1>;
			status = "disabled";
			linux,phandle = <0xfc>;
			phandle = <0xfc>;
		};

		spi@14d30000 {
			compatible = "samsung,exynos5433-spi";
			reg = <0x14d30000 0x100>;
			interrupts = <0x0 0x1b1 0x4>;
			dmas = <0x40 0xb 0x40 0xa>;
			dma-names = "tx", "rx";
			#address-cells = <0x1>;
			#size-cells = <0x0>;
			clocks = <0x3c 0x2 0x3c 0x20 0x3c 0x3c>;
			clock-names = "spi", "spi_busclk0", "spi_ioclk";
			samsung,spi-src-clk = <0x0>;
			pinctrl-names = "default";
			pinctrl-0 = <0x42>;
			num-cs = <0x1>;
			status = "okay";
			cs-gpios = <0x43 0x3 0x0>;
			linux,phandle = <0xfd>;
			phandle = <0xfd>;

			wm5110-codec@0 {
				compatible = "wlf,wm5110";
				reg = <0x0>;
				spi-max-frequency = <0x1312d00>;
				interrupt-parent = <0x44>;
				interrupts = <0x4 0x0>;
				clocks = <0x8 0x0 0x45 0x2>;
				clock-names = "mclk1", "mclk2";
				gpio-controller;
				#gpio-cells = <0x2>;
				wlf,micd-detect-debounce = <0x12c>;
				wlf,micd-bias-start-time = <0x1>;
				wlf,micd-rate = <0x7>;
				wlf,micd-dbtime = <0x1>;
				wlf,micd-force-micbias;
				wlf,micd-configs = <0x0 0x1 0x0>;
				wlf,hpdet-channel = <0x1>;
				wlf,gpsw = <0x1>;
				wlf,inmode = <0x2 0x0 0x2 0x0>;
				wlf,reset = <0x46 0x7 0x0>;
				wlf,ldoena = <0x47 0x0 0x0>;
				AVDD-supply = <0x48>;
				DBVDD1-supply = <0x48>;
				CPVDD-supply = <0x48>;
				DBVDD2-supply = <0x48>;
				DBVDD3-supply = <0x48>;
				linux,phandle = <0x98>;
				phandle = <0x98>;

				controller-data {
					samsung,spi-feedback-delay = <0x0>;
				};
			};
		};

		spi@14d40000 {
			compatible = "samsung,exynos5433-spi";
			reg = <0x14d40000 0x100>;
			interrupts = <0x0 0x1b2 0x4>;
			dmas = <0x40 0xd 0x40 0xc>;
			dma-names = "tx", "rx";
			#address-cells = <0x1>;
			#size-cells = <0x0>;
			clocks = <0x3c 0x1 0x3c 0x1f 0x3c 0x3b>;
			clock-names = "spi", "spi_busclk0", "spi_ioclk";
			samsung,spi-src-clk = <0x0>;
			pinctrl-names = "default";
			pinctrl-0 = <0x49>;
			num-cs = <0x1>;
			status = "disabled";
			linux,phandle = <0xfe>;
			phandle = <0xfe>;
		};

		spi@14d50000 {
			compatible = "samsung,exynos5433-spi";
			reg = <0x14d50000 0x100>;
			interrupts = <0x0 0x1bf 0x4>;
			dmas = <0x40 0x17 0x40 0x16>;
			dma-names = "tx", "rx";
			#address-cells = <0x1>;
			#size-cells = <0x0>;
			clocks = <0x3c 0x14 0x3c 0x1e 0x3c 0x37>;
			clock-names = "spi", "spi_busclk0", "spi_ioclk";
			samsung,spi-src-clk = <0x0>;
			pinctrl-names = "default";
			pinctrl-0 = <0x4a>;
			num-cs = <0x1>;
			status = "okay";
			no-cs-readback;
			linux,phandle = <0xff>;
			phandle = <0xff>;

			irled@0 {
				compatible = "ir-spi-led";
				reg = <0x0>;
				spi-max-frequency = <0x4c4b40>;
				power-supply = <0x4b>;
				duty-cycle = <0x3c>;
				led-active-low;

				controller-data {
					samsung,spi-feedback-delay = <0x0>;
				};
			};
		};

		spi@14d00000 {
			compatible = "samsung,exynos5433-spi";
			reg = <0x14d00000 0x100>;
			interrupts = <0x0 0x19c 0x4>;
			dmas = <0x40 0x19 0x40 0x18>;
			dma-names = "tx", "rx";
			#address-cells = <0x1>;
			#size-cells = <0x0>;
			clocks = <0x3c 0x13 0x3c 0x1d 0x3c 0x36>;
			clock-names = "spi", "spi_busclk0", "spi_ioclk";
			samsung,spi-src-clk = <0x0>;
			pinctrl-names = "default";
			pinctrl-0 = <0x4c>;
			num-cs = <0x1>;
			status = "disabled";
			linux,phandle = <0x100>;
			phandle = <0x100>;
		};

		adc@14d10000 {
			compatible = "samsung,exynos7-adc";
			reg = <0x14d10000 0x100>;
			interrupts = <0x0 0x1b6 0x4>;
			clock-names = "adc";
			clocks = <0x3c 0x30>;
			#io-channel-cells = <0x1>;
			io-channel-ranges;
			status = "okay";
			vdd-supply = <0x14>;
			linux,phandle = <0x4d>;
			phandle = <0x4d>;

			thermistor-ap {
				compatible = "murata,ncp03wf104";
				pullup-uv = <0x1b7740>;
				pullup-ohm = <0x186a0>;
				pulldown-ohm = <0x0>;
				io-channels = <0x4d 0x0>;
			};

			thermistor-battery {
				compatible = "murata,ncp03wf104";
				pullup-uv = <0x1b7740>;
				pullup-ohm = <0x186a0>;
				pulldown-ohm = <0x0>;
				io-channels = <0x4d 0x1>;
				#thermal-sensor-cells = <0x0>;
			};

			thermistor-charger {
				compatible = "murata,ncp03wf104";
				pullup-uv = <0x1b7740>;
				pullup-ohm = <0x186a0>;
				pulldown-ohm = <0x0>;
				io-channels = <0x4d 0x2>;
			};
		};

		pwm@14dd0000 {
			compatible = "samsung,exynos4210-pwm";
			reg = <0x14dd0000 0x100>;
			interrupts = <0x0 0x1a0 0x4 0x0 0x1a1 0x4 0x0 0x1a2 0x4 0x0 0x1a3 0x4 0x0 0x1a4 0x4>;
			samsung,pwm-outputs = <0x0 0x1 0x2 0x3>;
			clocks = <0x3c 0x2c>;
			clock-names = "timers";
			#pwm-cells = <0x3>;
			status = "okay";
			pinctrl-0 = <0x4e>;
			pinctrl-names = "default";
			linux,phandle = <0x60>;
			phandle = <0x60>;
		};

		hsi2c@14e40000 {
			compatible = "samsung,exynos7-hsi2c";
			reg = <0x14e40000 0x1000>;
			interrupts = <0x0 0x1ac 0x4>;
			#address-cells = <0x1>;
			#size-cells = <0x0>;
			pinctrl-names = "default";
			pinctrl-0 = <0x4f>;
			clocks = <0x3c 0xa>;
			clock-names = "hsi2c";
			status = "okay";
			clock-frequency = <0x2625a0>;
			linux,phandle = <0x101>;
			phandle = <0x101>;

			s2mps13-pmic@66 {
				compatible = "samsung,s2mps13-pmic";
				interrupt-parent = <0x44>;
				interrupts = <0x7 0x0>;
				reg = <0x66>;
				samsung,s2mps11-wrstbi-ground;

				clocks {
					compatible = "samsung,s2mps13-clk";
					#clock-cells = <0x1>;
					clock-output-names = "s2mps13_ap", "s2mps13_cp", "s2mps13_bt";
					linux,phandle = <0x45>;
					phandle = <0x45>;
				};

				regulators {

					LDO1 {
						regulator-name = "VDD_ALIVE_0.9V_AP";
						regulator-min-microvolt = <0xdbba0>;
						regulator-max-microvolt = <0xdbba0>;
						regulator-always-on;
						linux,phandle = <0x102>;
						phandle = <0x102>;
					};

					LDO2 {
						regulator-name = "VDDQ_MMC2_2.8V_AP";
						regulator-min-microvolt = <0x2ab980>;
						regulator-max-microvolt = <0x2ab980>;
						regulator-always-on;
						linux,phandle = <0x103>;
						phandle = <0x103>;

						regulator-state-mem {
							regulator-off-in-suspend;
						};
					};

					LDO3 {
						regulator-name = "VDD1_E_1.8V_AP";
						regulator-min-microvolt = <0x1b7740>;
						regulator-max-microvolt = <0x1b7740>;
						regulator-always-on;
						linux,phandle = <0x14>;
						phandle = <0x14>;
					};

					LDO4 {
						regulator-name = "VDD10_MIF_PLL_1.0V_AP";
						regulator-min-microvolt = <0x13d620>;
						regulator-max-microvolt = <0x13d620>;
						regulator-always-on;
						linux,phandle = <0x104>;
						phandle = <0x104>;

						regulator-state-mem {
							regulator-off-in-suspend;
						};
					};

					LDO5 {
						regulator-name = "VDD10_DPLL_1.0V_AP";
						regulator-min-microvolt = <0xf4240>;
						regulator-max-microvolt = <0xf4240>;
						regulator-always-on;
						linux,phandle = <0x105>;
						phandle = <0x105>;

						regulator-state-mem {
							regulator-off-in-suspend;
						};
					};

					LDO6 {
						regulator-name = "VDD10_MIPI2L_1.0V_AP";
						regulator-min-microvolt = <0xf4240>;
						regulator-max-microvolt = <0xf4240>;
						linux,phandle = <0x27>;
						phandle = <0x27>;

						regulator-state-mem {
							regulator-off-in-suspend;
						};
					};

					LDO7 {
						regulator-name = "VDD18_MIPI2L_1.8V_AP";
						regulator-min-microvolt = <0x1b7740>;
						regulator-max-microvolt = <0x1b7740>;
						regulator-always-on;
						linux,phandle = <0x28>;
						phandle = <0x28>;

						regulator-state-mem {
							regulator-off-in-suspend;
						};
					};

					LDO8 {
						regulator-name = "VDD18_LLI_1.8V_AP";
						regulator-min-microvolt = <0x1b7740>;
						regulator-max-microvolt = <0x1b7740>;
						regulator-always-on;
						linux,phandle = <0x106>;
						phandle = <0x106>;

						regulator-state-mem {
							regulator-off-in-suspend;
						};
					};

					LDO9 {
						regulator-name = "VDD18_ABB_ETC_1.8V_AP";
						regulator-min-microvolt = <0x1b7740>;
						regulator-max-microvolt = <0x1b7740>;
						regulator-always-on;
						linux,phandle = <0x107>;
						phandle = <0x107>;

						regulator-state-mem {
							regulator-off-in-suspend;
						};
					};

					LDO10 {
						regulator-name = "VDD33_USB30_3.0V_AP";
						regulator-min-microvolt = <0x2dc6c0>;
						regulator-max-microvolt = <0x2dc6c0>;
						linux,phandle = <0x66>;
						phandle = <0x66>;

						regulator-state-mem {
							regulator-off-in-suspend;
						};
					};

					LDO11 {
						regulator-name = "VDD_INT_M_1.0V_AP";
						regulator-min-microvolt = <0xf4240>;
						regulator-max-microvolt = <0xf4240>;
						regulator-always-on;
						linux,phandle = <0x108>;
						phandle = <0x108>;

						regulator-state-mem {
							regulator-off-in-suspend;
						};
					};

					LDO12 {
						regulator-name = "VDD_KFC_M_1.1V_AP";
						regulator-min-microvolt = <0xc3500>;
						regulator-max-microvolt = <0x149970>;
						regulator-always-on;
						linux,phandle = <0x109>;
						phandle = <0x109>;
					};

					LDO13 {
						regulator-name = "VDD_G3D_M_0.95V_AP";
						regulator-min-microvolt = <0xe7ef0>;
						regulator-max-microvolt = <0xe7ef0>;
						regulator-always-on;
						linux,phandle = <0x10a>;
						phandle = <0x10a>;

						regulator-state-mem {
							regulator-off-in-suspend;
						};
					};

					LDO14 {
						regulator-name = "VDDQ_M1_LDO_1.2V_AP";
						regulator-min-microvolt = <0x124f80>;
						regulator-max-microvolt = <0x124f80>;
						regulator-always-on;
						linux,phandle = <0x10b>;
						phandle = <0x10b>;

						regulator-state-mem {
							regulator-off-in-suspend;
						};
					};

					LDO15 {
						regulator-name = "VDDQ_M2_LDO_1.2V_AP";
						regulator-min-microvolt = <0x124f80>;
						regulator-max-microvolt = <0x124f80>;
						regulator-always-on;
						linux,phandle = <0x10c>;
						phandle = <0x10c>;

						regulator-state-mem {
							regulator-off-in-suspend;
						};
					};

					LDO16 {
						regulator-name = "VDDQ_EFUSE";
						regulator-min-microvolt = <0x155cc0>;
						regulator-max-microvolt = <0x33e140>;
						regulator-always-on;
						linux,phandle = <0x10d>;
						phandle = <0x10d>;
					};

					LDO17 {
						regulator-name = "V_TFLASH_2.8V_AP";
						regulator-min-microvolt = <0x2ab980>;
						regulator-max-microvolt = <0x2ab980>;
						linux,phandle = <0x10e>;
						phandle = <0x10e>;
					};

					LDO18 {
						regulator-name = "V_CODEC_1.8V_AP";
						regulator-min-microvolt = <0x1b7740>;
						regulator-max-microvolt = <0x1b7740>;
						linux,phandle = <0x48>;
						phandle = <0x48>;
					};

					LDO19 {
						regulator-name = "VDDA_1.8V_COMP";
						regulator-min-microvolt = <0x1b7740>;
						regulator-max-microvolt = <0x1b7740>;
						regulator-always-on;
						linux,phandle = <0x10f>;
						phandle = <0x10f>;
					};

					LDO20 {
						regulator-name = "VCC_2.8V_AP";
						regulator-min-microvolt = <0x2ab980>;
						regulator-max-microvolt = <0x2ab980>;
						regulator-always-on;
						linux,phandle = <0x110>;
						phandle = <0x110>;
					};

					LDO21 {
						regulator-name = "VT_CAM_1.8V";
						regulator-min-microvolt = <0x1b7740>;
						regulator-max-microvolt = <0x1b7740>;
						linux,phandle = <0x111>;
						phandle = <0x111>;
					};

					LDO22 {
						regulator-name = "CAM_IO_1.8V_AP";
						regulator-min-microvolt = <0x1b7740>;
						regulator-max-microvolt = <0x1b7740>;
						linux,phandle = <0x112>;
						phandle = <0x112>;
					};

					LDO23 {
						regulator-name = "CAM_SEN_CORE_1.05V_AP";
						regulator-min-microvolt = <0x100590>;
						regulator-max-microvolt = <0x100590>;
						linux,phandle = <0x113>;
						phandle = <0x113>;
					};

					LDO24 {
						regulator-name = "VT_CAM_1.2V";
						regulator-min-microvolt = <0x124f80>;
						regulator-max-microvolt = <0x124f80>;
						linux,phandle = <0x114>;
						phandle = <0x114>;
					};

					LDO25 {
						regulator-name = "UNUSED_LDO25";
						regulator-min-microvolt = <0x2ab980>;
						regulator-max-microvolt = <0x2ab980>;
						linux,phandle = <0x115>;
						phandle = <0x115>;
					};

					LDO26 {
						regulator-name = "CAM_AF_2.8V_AP";
						regulator-min-microvolt = <0x2ab980>;
						regulator-max-microvolt = <0x2ab980>;
						linux,phandle = <0x116>;
						phandle = <0x116>;
					};

					LDO27 {
						regulator-name = "VCC_3.0V_LCD_AP";
						regulator-min-microvolt = <0x2dc6c0>;
						regulator-max-microvolt = <0x2dc6c0>;
						linux,phandle = <0x2b>;
						phandle = <0x2b>;
					};

					LDO28 {
						regulator-name = "VCC_1.8V_LCD_AP";
						regulator-min-microvolt = <0x1b7740>;
						regulator-max-microvolt = <0x1b7740>;
						linux,phandle = <0x2c>;
						phandle = <0x2c>;
					};

					LDO29 {
						regulator-name = "VT_CAM_2.8V";
						regulator-min-microvolt = <0x2dc6c0>;
						regulator-max-microvolt = <0x2dc6c0>;
						linux,phandle = <0x117>;
						phandle = <0x117>;
					};

					LDO30 {
						regulator-name = "TSP_AVDD_3.3V_AP";
						regulator-min-microvolt = <0x325aa0>;
						regulator-max-microvolt = <0x325aa0>;
						linux,phandle = <0x56>;
						phandle = <0x56>;
					};

					LDO31 {
						regulator-name = "TSP_VDD_1.85V_AP";
						regulator-min-microvolt = <0x1c3a90>;
						regulator-max-microvolt = <0x1c3a90>;
						linux,phandle = <0x57>;
						phandle = <0x57>;
					};

					LDO32 {
						regulator-name = "VTOUCH_1.8V_AP";
						regulator-min-microvolt = <0x1b7740>;
						regulator-max-microvolt = <0x1b7740>;
						linux,phandle = <0x62>;
						phandle = <0x62>;
					};

					LDO33 {
						regulator-name = "VTOUCH_LED_3.3V";
						regulator-min-microvolt = <0x2625a0>;
						regulator-max-microvolt = <0x325aa0>;
						regulator-ramp-delay = <0x30d4>;
						linux,phandle = <0x63>;
						phandle = <0x63>;
					};

					LDO34 {
						regulator-name = "VCC_1.8V_MHL_AP";
						regulator-min-microvolt = <0xf4240>;
						regulator-max-microvolt = <0x200b20>;
						linux,phandle = <0x5b>;
						phandle = <0x5b>;
					};

					LDO35 {
						regulator-name = "OIS_VM_2.8V";
						regulator-min-microvolt = <0x1b7740>;
						regulator-max-microvolt = <0x2ab980>;
						linux,phandle = <0x118>;
						phandle = <0x118>;
					};

					LDO36 {
						regulator-name = "VSIL_1.0V";
						regulator-min-microvolt = <0xf4240>;
						regulator-max-microvolt = <0xf4240>;
						linux,phandle = <0x5a>;
						phandle = <0x5a>;
					};

					LDO37 {
						regulator-name = "VF_1.8V";
						regulator-min-microvolt = <0x1b7740>;
						regulator-max-microvolt = <0x1b7740>;
						linux,phandle = <0x119>;
						phandle = <0x119>;
					};

					LDO38 {
						regulator-name = "VCC_3.0V_MOTOR_AP";
						regulator-min-microvolt = <0x2dc6c0>;
						regulator-max-microvolt = <0x2dc6c0>;
						linux,phandle = <0x5f>;
						phandle = <0x5f>;
					};

					LDO39 {
						regulator-name = "V_HRM_1.8V";
						regulator-min-microvolt = <0x1b7740>;
						regulator-max-microvolt = <0x1b7740>;
						linux,phandle = <0x11a>;
						phandle = <0x11a>;
					};

					LDO40 {
						regulator-name = "V_HRM_3.3V";
						regulator-min-microvolt = <0x325aa0>;
						regulator-max-microvolt = <0x325aa0>;
						linux,phandle = <0x11b>;
						phandle = <0x11b>;
					};

					BUCK1 {
						regulator-name = "VDD_MIF_0.9V_AP";
						regulator-min-microvolt = <0x927c0>;
						regulator-max-microvolt = <0x16e360>;
						regulator-always-on;
						linux,phandle = <0x11c>;
						phandle = <0x11c>;

						regulator-state-mem {
							regulator-off-in-suspend;
						};
					};

					BUCK2 {
						regulator-name = "VDD_EGL_1.0V_AP";
						regulator-min-microvolt = <0xdbba0>;
						regulator-max-microvolt = <0x13d620>;
						regulator-always-on;
						linux,phandle = <0x7>;
						phandle = <0x7>;

						regulator-state-mem {
							regulator-off-in-suspend;
						};
					};

					BUCK3 {
						regulator-name = "VDD_KFC_1.0V_AP";
						regulator-min-microvolt = <0xc3500>;
						regulator-max-microvolt = <0x124f80>;
						regulator-always-on;
						linux,phandle = <0x4>;
						phandle = <0x4>;

						regulator-state-mem {
							regulator-off-in-suspend;
						};
					};

					BUCK4 {
						regulator-name = "VDD_INT_0.95V_AP";
						regulator-min-microvolt = <0x927c0>;
						regulator-max-microvolt = <0x16e360>;
						regulator-always-on;
						linux,phandle = <0x7d>;
						phandle = <0x7d>;

						regulator-state-mem {
							regulator-off-in-suspend;
						};
					};

					BUCK5 {
						regulator-name = "VDD_DISP_CAM0_0.9V_AP";
						regulator-min-microvolt = <0x927c0>;
						regulator-max-microvolt = <0x16e360>;
						regulator-always-on;
						linux,phandle = <0x11d>;
						phandle = <0x11d>;

						regulator-state-mem {
							regulator-off-in-suspend;
						};
					};

					BUCK6 {
						regulator-name = "VDD_G3D_0.9V_AP";
						regulator-min-microvolt = <0x927c0>;
						regulator-max-microvolt = <0x16e360>;
						regulator-always-on;
						linux,phandle = <0x11e>;
						phandle = <0x11e>;

						regulator-state-mem {
							regulator-off-in-suspend;
						};
					};

					BUCK7 {
						regulator-name = "VDD_MEM1_1.2V_AP";
						regulator-min-microvolt = <0x124f80>;
						regulator-max-microvolt = <0x124f80>;
						regulator-always-on;
						linux,phandle = <0x11f>;
						phandle = <0x11f>;
					};

					BUCK8 {
						regulator-name = "VDD_LLDO_1.35V_AP";
						regulator-min-microvolt = <0x149970>;
						regulator-max-microvolt = <0x325aa0>;
						regulator-always-on;
						linux,phandle = <0x120>;
						phandle = <0x120>;
					};

					BUCK9 {
						regulator-name = "VDD_MLDO_2.0V_AP";
						regulator-min-microvolt = <0x149970>;
						regulator-max-microvolt = <0x325aa0>;
						regulator-always-on;
						linux,phandle = <0x121>;
						phandle = <0x121>;
					};

					BUCK10 {
						regulator-name = "vdd_mem2";
						regulator-min-microvolt = <0x86470>;
						regulator-max-microvolt = <0x16e360>;
						regulator-always-on;
						linux,phandle = <0x122>;
						phandle = <0x122>;
					};
				};
			};
		};

		hsi2c@14e50000 {
			compatible = "samsung,exynos7-hsi2c";
			reg = <0x14e50000 0x1000>;
			interrupts = <0x0 0x1ad 0x4>;
			#address-cells = <0x1>;
			#size-cells = <0x0>;
			pinctrl-names = "default";
			pinctrl-0 = <0x50>;
			clocks = <0x3c 0x9>;
			clock-names = "hsi2c";
			status = "disabled";
			linux,phandle = <0x123>;
			phandle = <0x123>;
		};

		hsi2c@14e60000 {
			compatible = "samsung,exynos7-hsi2c";
			reg = <0x14e60000 0x1000>;
			interrupts = <0x0 0x1ae 0x4>;
			#address-cells = <0x1>;
			#size-cells = <0x0>;
			pinctrl-names = "default";
			pinctrl-0 = <0x51>;
			clocks = <0x3c 0x8>;
			clock-names = "hsi2c";
			status = "disabled";
			linux,phandle = <0x124>;
			phandle = <0x124>;
		};

		hsi2c@14e70000 {
			compatible = "samsung,exynos7-hsi2c";
			reg = <0x14e70000 0x1000>;
			interrupts = <0x0 0x1af 0x4>;
			#address-cells = <0x1>;
			#size-cells = <0x0>;
			pinctrl-names = "default";
			pinctrl-0 = <0x52>;
			clocks = <0x3c 0x7>;
			clock-names = "hsi2c";
			status = "disabled";
			linux,phandle = <0x125>;
			phandle = <0x125>;
		};

		hsi2c@14ec0000 {
			compatible = "samsung,exynos7-hsi2c";
			reg = <0x14ec0000 0x1000>;
			interrupts = <0x0 0x1a8 0x4>;
			#address-cells = <0x1>;
			#size-cells = <0x0>;
			pinctrl-names = "default";
			pinctrl-0 = <0x53>;
			clocks = <0x3c 0x1c>;
			clock-names = "hsi2c";
			status = "disabled";
			linux,phandle = <0x126>;
			phandle = <0x126>;
		};

		hsi2c@14ed0000 {
			compatible = "samsung,exynos7-hsi2c";
			reg = <0x14ed0000 0x1000>;
			interrupts = <0x0 0x1a9 0x4>;
			#address-cells = <0x1>;
			#size-cells = <0x0>;
			pinctrl-names = "default";
			pinctrl-0 = <0x54>;
			clocks = <0x3c 0x1b>;
			clock-names = "hsi2c";
			status = "okay";
			linux,phandle = <0x127>;
			phandle = <0x127>;

			touchscreen@49 {
				compatible = "st,stmfts";
				reg = <0x49>;
				interrupt-parent = <0x55>;
				interrupts = <0x1 0x8>;
				avdd-supply = <0x56>;
				vdd-supply = <0x57>;
				touchscreen-size-x = <0x59f>;
				touchscreen-size-y = <0x9ff>;
				linux,phandle = <0x128>;
				phandle = <0x128>;
			};
		};

		hsi2c@14ee0000 {
			compatible = "samsung,exynos7-hsi2c";
			reg = <0x14ee0000 0x1000>;
			interrupts = <0x0 0x1aa 0x4>;
			#address-cells = <0x1>;
			#size-cells = <0x0>;
			pinctrl-names = "default";
			pinctrl-0 = <0x58>;
			clocks = <0x3c 0x1a>;
			clock-names = "hsi2c";
			status = "disabled";
			linux,phandle = <0x129>;
			phandle = <0x129>;
		};

		hsi2c@14ef0000 {
			compatible = "samsung,exynos7-hsi2c";
			reg = <0x14ef0000 0x1000>;
			interrupts = <0x0 0x1ab 0x4>;
			#address-cells = <0x1>;
			#size-cells = <0x0>;
			pinctrl-names = "default";
			pinctrl-0 = <0x59>;
			clocks = <0x3c 0x19>;
			clock-names = "hsi2c";
			status = "okay";
			linux,phandle = <0x12a>;
			phandle = <0x12a>;

			sii8620@39 {
				reg = <0x39>;
				compatible = "sil,sii8620";
				cvcc10-supply = <0x5a>;
				iovcc18-supply = <0x5b>;
				interrupt-parent = <0x47>;
				interrupts = <0x2 0x4>;
				reset-gpios = <0x5c 0x0 0x1>;
				clocks = <0x8 0x0>;
				clock-names = "xtal";

				port {

					endpoint {
						remote-endpoint = <0x5d>;
						linux,phandle = <0x35>;
						phandle = <0x35>;
					};
				};
			};
		};

		hsi2c@14d90000 {
			compatible = "samsung,exynos7-hsi2c";
			reg = <0x14d90000 0x1000>;
			interrupts = <0x0 0x1bb 0x4>;
			#address-cells = <0x1>;
			#size-cells = <0x0>;
			pinctrl-names = "default";
			pinctrl-0 = <0x5e>;
			clocks = <0x3c 0x18>;
			clock-names = "hsi2c";
			status = "okay";
			linux,phandle = <0x12b>;
			phandle = <0x12b>;

			max77843@66 {
				compatible = "maxim,max77843";
				interrupt-parent = <0x55>;
				interrupts = <0x5 0x2>;
				reg = <0x66>;

				max77843-muic {
					compatible = "maxim,max77843-muic";
					linux,phandle = <0x68>;
					phandle = <0x68>;
				};

				regulators {
					compatible = "maxim,max77843-regulator";

					SAFEOUT1 {
						regulator-name = "SAFEOUT1";
						regulator-min-microvolt = <0x325aa0>;
						regulator-max-microvolt = <0x4b87f0>;
						linux,phandle = <0x69>;
						phandle = <0x69>;
					};

					SAFEOUT2 {
						regulator-name = "SAFEOUT2";
						regulator-min-microvolt = <0x325aa0>;
						regulator-max-microvolt = <0x4b87f0>;
						linux,phandle = <0x12c>;
						phandle = <0x12c>;
					};

					CHARGER {
						regulator-name = "CHARGER";
						regulator-min-microamp = <0x186a0>;
						regulator-max-microamp = <0x3010b0>;
						linux,phandle = <0x12d>;
						phandle = <0x12d>;
					};
				};

				max77843-haptic {
					compatible = "maxim,max77843-haptic";
					haptic-supply = <0x5f>;
					pwms = <0x60 0x0 0x8386 0x0>;
					pwm-names = "haptic";
					linux,phandle = <0x12e>;
					phandle = <0x12e>;
				};
			};
		};

		hsi2c@14da0000 {
			compatible = "samsung,exynos7-hsi2c";
			reg = <0x14da0000 0x1000>;
			interrupts = <0x0 0x1bc 0x4>;
			#address-cells = <0x1>;
			#size-cells = <0x0>;
			pinctrl-names = "default";
			pinctrl-0 = <0x61>;
			clocks = <0x3c 0x17>;
			clock-names = "hsi2c";
			status = "okay";
			linux,phandle = <0x12f>;
			phandle = <0x12f>;

			touchkey@20 {
				compatible = "cypress,tm2-touchkey";
				reg = <0x20>;
				interrupt-parent = <0x33>;
				interrupts = <0x2 0x2>;
				vcc-supply = <0x62>;
				vdd-supply = <0x63>;
			};
		};

		hsi2c@14de0000 {
			compatible = "samsung,exynos7-hsi2c";
			reg = <0x14de0000 0x1000>;
			interrupts = <0x0 0x1bd 0x4>;
			#address-cells = <0x1>;
			#size-cells = <0x0>;
			pinctrl-names = "default";
			pinctrl-0 = <0x64>;
			clocks = <0x3c 0x16>;
			clock-names = "hsi2c";
			status = "disabled";
			linux,phandle = <0x130>;
			phandle = <0x130>;
		};

		hsi2c@14df0000 {
			compatible = "samsung,exynos7-hsi2c";
			reg = <0x14df0000 0x1000>;
			interrupts = <0x0 0x1be 0x4>;
			#address-cells = <0x1>;
			#size-cells = <0x0>;
			pinctrl-names = "default";
			pinctrl-0 = <0x65>;
			clocks = <0x3c 0x15>;
			clock-names = "hsi2c";
			status = "okay";
			linux,phandle = <0x32>;
			phandle = <0x32>;
		};

		usbdrd {
			compatible = "samsung,exynos5250-dwusb3";
			clocks = <0xd 0x3b 0xd 0x72>;
			clock-names = "usbdrd30", "usbdrd30_susp_clk";
			#address-cells = <0x1>;
			#size-cells = <0x1>;
			ranges;
			status = "okay";
			vdd33-supply = <0x66>;
			vdd10-supply = <0x27>;
			linux,phandle = <0x131>;
			phandle = <0x131>;

			dwc3@15400000 {
				compatible = "snps,dwc3";
				reg = <0x15400000 0x10000>;
				interrupts = <0x0 0xe7 0x4>;
				phys = <0x67 0x0 0x67 0x1>;
				phy-names = "usb2-phy", "usb3-phy";
				dr_mode = "otg";
				extcon = <0x68>;
				linux,phandle = <0x132>;
				phandle = <0x132>;
			};
		};

		phy@15500000 {
			compatible = "samsung,exynos5433-usbdrd-phy";
			reg = <0x15500000 0x100>;
			clocks = <0xd 0x3b 0x9 0xd 0x6e 0xd 0x6d 0xd 0x72>;
			clock-names = "phy", "ref", "phy_utmi", "phy_pipe", "itp";
			#phy-cells = <0x1>;
			samsung,pmu-syscon = <0x8>;
			status = "okay";
			vbus-supply = <0x69>;
			linux,phandle = <0x67>;
			phandle = <0x67>;
		};

		phy@15580000 {
			compatible = "samsung,exynos5433-usbdrd-phy";
			reg = <0x15580000 0x100>;
			clocks = <0xd 0x3a 0x9 0xd 0x64 0xd 0x63 0xd 0x71>;
			clock-names = "phy", "ref", "phy_utmi", "phy_pipe", "itp";
			#phy-cells = <0x1>;
			samsung,pmu-syscon = <0x8>;
			status = "disabled";
			linux,phandle = <0x6a>;
			phandle = <0x6a>;
		};

		usbhost {
			compatible = "samsung,exynos5250-dwusb3";
			clocks = <0xd 0x3a 0xd 0x71>;
			clock-names = "usbdrd30", "usbdrd30_susp_clk";
			#address-cells = <0x1>;
			#size-cells = <0x1>;
			ranges;
			status = "disabled";
			linux,phandle = <0x133>;
			phandle = <0x133>;

			dwc3@15a00000 {
				compatible = "snps,dwc3";
				reg = <0x15a00000 0x10000>;
				interrupts = <0x0 0xf4 0x4>;
				phys = <0x6a 0x0 0x6a 0x1>;
				phy-names = "usb2-phy", "usb3-phy";
				linux,phandle = <0x134>;
				phandle = <0x134>;
			};
		};

		mshc@15540000 {
			compatible = "samsung,exynos7-dw-mshc-smu";
			interrupts = <0x0 0xe1 0x4>;
			#address-cells = <0x1>;
			#size-cells = <0x0>;
			reg = <0x15540000 0x2000>;
			clocks = <0xd 0x37 0xd 0x3f>;
			clock-names = "biu", "ciu";
			fifo-depth = <0x80>;
			status = "okay";
			mmc-hs200-1_8v;
			mmc-hs400-1_8v;
			cap-mmc-highspeed;
			non-removable;
			card-detect-delay = <0xc8>;
			samsung,dw-mshc-ciu-div = <0x3>;
			samsung,dw-mshc-sdr-timing = <0x0 0x4>;
			samsung,dw-mshc-ddr-timing = <0x0 0x2>;
			samsung,dw-mshc-hs400-timing = <0x0 0x3>;
			samsung,read-strobe-delay = <0x5a>;
			pinctrl-names = "default";
			pinctrl-0 = <0x6b 0x6c 0x6d 0x6e 0x6f 0x70 0x71>;
			bus-width = <0x8>;
			assigned-clocks = <0xc 0xcd>;
			assigned-clock-rates = <0x2faf0800>;
			linux,phandle = <0x135>;
			phandle = <0x135>;
		};

		mshc@15550000 {
			compatible = "samsung,exynos7-dw-mshc-smu";
			interrupts = <0x0 0xe2 0x4>;
			#address-cells = <0x1>;
			#size-cells = <0x0>;
			reg = <0x15550000 0x2000>;
			clocks = <0xd 0x36 0xd 0x3e>;
			clock-names = "biu", "ciu";
			fifo-depth = <0x40>;
			status = "disabled";
			linux,phandle = <0x136>;
			phandle = <0x136>;
		};

		mshc@15560000 {
			compatible = "samsung,exynos7-dw-mshc-smu";
			interrupts = <0x0 0xe3 0x4>;
			#address-cells = <0x1>;
			#size-cells = <0x0>;
			reg = <0x15560000 0x2000>;
			clocks = <0xd 0x35 0xd 0x3d>;
			clock-names = "biu", "ciu";
			fifo-depth = <0x80>;
			status = "okay";
			cap-sd-highspeed;
			disable-wp;
			cd-gpios = <0x72 0x4 0x0>;
			cd-inverted;
			card-detect-delay = <0xc8>;
			samsung,dw-mshc-ciu-div = <0x3>;
			samsung,dw-mshc-sdr-timing = <0x0 0x4>;
			samsung,dw-mshc-ddr-timing = <0x0 0x2>;
			pinctrl-names = "default";
			pinctrl-0 = <0x73 0x74 0x75 0x76>;
			bus-width = <0x4>;
			linux,phandle = <0x137>;
			phandle = <0x137>;
		};

		amba {
			compatible = "simple-bus";
			#address-cells = <0x1>;
			#size-cells = <0x1>;
			ranges;

			pdma@15610000 {
				compatible = "arm,pl330", "arm,primecell";
				reg = <0x15610000 0x1000>;
				interrupts = <0x0 0xe4 0x4>;
				clocks = <0xd 0x41>;
				clock-names = "apb_pclk";
				#dma-cells = <0x1>;
				#dma-channels = <0x8>;
				#dma-requests = <0x20>;
				linux,phandle = <0x40>;
				phandle = <0x40>;
			};

			pdma@15600000 {
				compatible = "arm,pl330", "arm,primecell";
				reg = <0x15600000 0x1000>;
				interrupts = <0x0 0xf6 0x4>;
				clocks = <0xd 0x40>;
				clock-names = "apb_pclk";
				#dma-cells = <0x1>;
				#dma-channels = <0x8>;
				#dma-requests = <0x20>;
				linux,phandle = <0x138>;
				phandle = <0x138>;
			};
		};

		audio-subsystem@11400000 {
			compatible = "samsung,exynos5433-lpass";
			reg = <0x11400000 0x100 0x11500000 0x8>;
			clocks = <0xf 0x25>;
			clock-names = "sfr0_ctrl";
			samsung,pmu-syscon = <0x8>;
			#address-cells = <0x1>;
			#size-cells = <0x1>;
			ranges;

			adma@11420000 {
				compatible = "arm,pl330", "arm,primecell";
				reg = <0x11420000 0x1000>;
				interrupts = <0x0 0x49 0x4>;
				clocks = <0xf 0x18>;
				clock-names = "apb_pclk";
				#dma-cells = <0x1>;
				#dma-channels = <0x8>;
				#dma-requests = <0x20>;
				linux,phandle = <0x77>;
				phandle = <0x77>;
			};

			i2s0@11440000 {
				compatible = "samsung,exynos7-i2s";
				reg = <0x11440000 0x100>;
				dmas = <0x77 0x0 0x77 0x2>;
				dma-names = "tx", "rx";
				interrupts = <0x0 0x46 0x4>;
				#address-cells = <0x1>;
				#size-cells = <0x0>;
				clocks = <0xf 0x23 0xf 0x2f 0xf 0x2e>;
				clock-names = "iis", "i2s_opclk0", "i2s_opclk1";
				pinctrl-names = "default";
				pinctrl-0 = <0x78>;
				status = "okay";
				linux,phandle = <0x99>;
				phandle = <0x99>;
			};

			serial@11460000 {
				compatible = "samsung,exynos5433-uart";
				reg = <0x11460000 0x100>;
				interrupts = <0x0 0x43 0x4>;
				clocks = <0xf 0x21 0xf 0x2c>;
				clock-names = "uart", "clk_uart_baud0";
				pinctrl-names = "default";
				pinctrl-0 = <0x79>;
				status = "disabled";
				linux,phandle = <0x139>;
				phandle = <0x139>;
			};
		};

		bus0 {
			compatible = "samsung,exynos-bus";
			clocks = <0xc 0xdd>;
			clock-names = "bus";
			operating-points-v2 = <0x7a>;
			status = "okay";
			devfreq-events = <0x7b 0x7c>;
			vdd-supply = <0x7d>;
			exynos,saturation-ratio = <0xa>;
			linux,phandle = <0x7f>;
			phandle = <0x7f>;
		};

		bus1 {
			compatible = "samsung,exynos-bus";
			clocks = <0xc 0xdc>;
			clock-names = "bus";
			operating-points-v2 = <0x7e>;
			status = "okay";
			devfreq = <0x7f>;
			linux,phandle = <0x13a>;
			phandle = <0x13a>;
		};

		bus2 {
			compatible = "samsung,exynos-bus";
			clocks = <0xc 0xe9>;
			clock-names = "bus";
			operating-points-v2 = <0x80>;
			status = "okay";
			devfreq = <0x7f>;
			linux,phandle = <0x13b>;
			phandle = <0x13b>;
		};

		bus3 {
			compatible = "samsung,exynos-bus";
			clocks = <0xc 0xed>;
			clock-names = "bus";
			operating-points-v2 = <0x81>;
			status = "okay";
			devfreq = <0x7f>;
			linux,phandle = <0x13c>;
			phandle = <0x13c>;
		};

		bus4 {
			compatible = "samsung,exynos-bus";
			clocks = <0xc 0xea>;
			clock-names = "bus";
			operating-points-v2 = <0x7a>;
			status = "okay";
			devfreq = <0x7f>;
			linux,phandle = <0x13d>;
			phandle = <0x13d>;
		};

		bus5 {
			compatible = "samsung,exynos-bus";
			clocks = <0xc 0xec>;
			clock-names = "bus";
			operating-points-v2 = <0x7a>;
			status = "okay";
			devfreq = <0x7f>;
			linux,phandle = <0x13e>;
			phandle = <0x13e>;
		};

		bus6 {
			compatible = "samsung,exynos-bus";
			clocks = <0xc 0xeb>;
			clock-names = "bus";
			operating-points-v2 = <0x7a>;
			status = "okay";
			devfreq = <0x7f>;
			linux,phandle = <0x13f>;
			phandle = <0x13f>;
		};

		bus7 {
			compatible = "samsung,exynos-bus";
			clocks = <0xc 0xe0>;
			clock-names = "bus";
			operating-points-v2 = <0x81>;
			status = "okay";
			devfreq = <0x7f>;
			linux,phandle = <0x140>;
			phandle = <0x140>;
		};

		bus8 {
			compatible = "samsung,exynos-bus";
			clocks = <0xc 0xe1>;
			clock-names = "bus";
			operating-points-v2 = <0x81>;
			status = "okay";
			devfreq = <0x7f>;
			linux,phandle = <0x141>;
			phandle = <0x141>;
		};

		bus9 {
			compatible = "samsung,exynos-bus";
			clocks = <0xb 0x97>;
			clock-names = "bus";
			operating-points-v2 = <0x82>;
			status = "okay";
			devfreq = <0x7f>;
			linux,phandle = <0x142>;
			phandle = <0x142>;
		};

		opp_table2 {
			compatible = "operating-points-v2";
			opp-shared;
			linux,phandle = <0x7a>;
			phandle = <0x7a>;

			opp-400000000 {
				opp-hz = <0x0 0x17d78400>;
				opp-microvolt = <0x106738>;
			};

			opp-267000000 {
				opp-hz = <0x0 0xfea18c0>;
				opp-microvolt = <0xf4240>;
			};

			opp-200000000 {
				opp-hz = <0x0 0xbebc200>;
				opp-microvolt = <0xee098>;
			};

			opp-160000000 {
				opp-hz = <0x0 0x9896800>;
				opp-microvolt = <0xeafc4>;
			};

			opp-134000000 {
				opp-hz = <0x0 0x7fcad80>;
				opp-microvolt = <0xe7ef0>;
			};

			opp-100000000 {
				opp-hz = <0x0 0x5f5e100>;
				opp-microvolt = <0xe4e1c>;
			};
		};

		opp_table3 {
			compatible = "operating-points-v2";
			linux,phandle = <0x7e>;
			phandle = <0x7e>;

			opp-267000000 {
				opp-hz = <0x0 0xfea18c0>;
			};

			opp-200000000 {
				opp-hz = <0x0 0xbebc200>;
			};

			opp-160000000 {
				opp-hz = <0x0 0x9896800>;
			};

			opp-134000000 {
				opp-hz = <0x0 0x7fcad80>;
			};

			opp-100000000 {
				opp-hz = <0x0 0x5f5e100>;
			};
		};

		opp_table4 {
			compatible = "operating-points-v2";
			linux,phandle = <0x80>;
			phandle = <0x80>;

			opp-333000000 {
				opp-hz = <0x0 0x13d92d40>;
			};

			opp-222000000 {
				opp-hz = <0x0 0xd3b7380>;
			};

			opp-166500000 {
				opp-hz = <0x0 0x9ec96a0>;
			};
		};

		opp_table5 {
			compatible = "operating-points-v2";
			opp-shared;
			linux,phandle = <0x81>;
			phandle = <0x81>;

			opp-400000000 {
				opp-hz = <0x0 0x17d78400>;
			};

			opp-267000000 {
				opp-hz = <0x0 0xfea18c0>;
			};

			opp-200000000 {
				opp-hz = <0x0 0xbebc200>;
			};

			opp-160000000 {
				opp-hz = <0x0 0x9896800>;
			};

			opp-134000000 {
				opp-hz = <0x0 0x7fcad80>;
			};

			opp-100000000 {
				opp-hz = <0x0 0x5f5e100>;
			};
		};

		opp_table6 {
			compatible = "operating-points-v2";
			linux,phandle = <0x82>;
			phandle = <0x82>;

			opp-400000000 {
				opp-hz = <0x0 0x17d78400>;
			};

			opp-200000000 {
				opp-hz = <0x0 0xbebc200>;
			};

			opp-134000000 {
				opp-hz = <0x0 0x7fcad80>;
			};

			opp-100000000 {
				opp-hz = <0x0 0x5f5e100>;
			};
		};
	};

	timer {
		compatible = "arm,armv8-timer";
		interrupts = <0x1 0xd 0xff04 0x1 0xe 0xff04 0x1 0xb 0xff04 0x1 0xa 0xff04>;
		clock-frequency = <0x16e3600>;
		linux,phandle = <0x143>;
		phandle = <0x143>;
	};

	thermal-zones {

		atlas0-thermal {
			thermal-sensors = <0x83>;
			polling-delay-passive = <0x0>;
			polling-delay = <0x0>;
			linux,phandle = <0x144>;
			phandle = <0x144>;

			trips {

				atlas0-alert-0 {
					temperature = <0xfde8>;
					hysteresis = <0x3e8>;
					type = "active";
					linux,phandle = <0x84>;
					phandle = <0x84>;
				};

				atlas0-alert-1 {
					temperature = <0x11170>;
					hysteresis = <0x3e8>;
					type = "active";
					linux,phandle = <0x86>;
					phandle = <0x86>;
				};

				atlas0-alert-2 {
					temperature = <0x124f8>;
					hysteresis = <0x3e8>;
					type = "active";
					linux,phandle = <0x87>;
					phandle = <0x87>;
				};

				atlas0-alert-3 {
					temperature = <0x13880>;
					hysteresis = <0x3e8>;
					type = "active";
					linux,phandle = <0x88>;
					phandle = <0x88>;
				};

				atlas0-alert-4 {
					temperature = <0x14c08>;
					hysteresis = <0x3e8>;
					type = "active";
					linux,phandle = <0x89>;
					phandle = <0x89>;
				};

				atlas0-alert-5 {
					temperature = <0x15f90>;
					hysteresis = <0x3e8>;
					type = "active";
					linux,phandle = <0x8a>;
					phandle = <0x8a>;
				};

				atlas0-alert-6 {
					temperature = <0x17318>;
					hysteresis = <0x3e8>;
					type = "active";
					linux,phandle = <0x8b>;
					phandle = <0x8b>;
				};
			};

			cooling-maps {

				map0 {
					trip = <0x84>;
					cooling-device = <0x85 0x1 0x2>;
				};

				map1 {
					trip = <0x86>;
					cooling-device = <0x85 0x2 0x3>;
				};

				map2 {
					trip = <0x87>;
					cooling-device = <0x85 0x3 0x4>;
				};

				map3 {
					trip = <0x88>;
					cooling-device = <0x85 0x4 0x5>;
				};

				map4 {
					trip = <0x89>;
					cooling-device = <0x85 0x5 0x7>;
				};

				map5 {
					trip = <0x8a>;
					cooling-device = <0x85 0x7 0x9>;
				};

				map6 {
					trip = <0x8b>;
					cooling-device = <0x85 0x9 0xe>;
				};
			};
		};

		atlas1-thermal {
			thermal-sensors = <0x8c>;
			polling-delay-passive = <0x0>;
			polling-delay = <0x0>;
			linux,phandle = <0x145>;
			phandle = <0x145>;

			trips {

				atlas1-alert-0 {
					temperature = <0xfde8>;
					hysteresis = <0x3e8>;
					type = "active";
					linux,phandle = <0x146>;
					phandle = <0x146>;
				};

				atlas1-alert-1 {
					temperature = <0x11170>;
					hysteresis = <0x3e8>;
					type = "active";
					linux,phandle = <0x147>;
					phandle = <0x147>;
				};

				atlas1-alert-2 {
					temperature = <0x124f8>;
					hysteresis = <0x3e8>;
					type = "active";
					linux,phandle = <0x148>;
					phandle = <0x148>;
				};

				atlas1-alert-3 {
					temperature = <0x13880>;
					hysteresis = <0x3e8>;
					type = "active";
					linux,phandle = <0x149>;
					phandle = <0x149>;
				};

				atlas1-alert-4 {
					temperature = <0x14c08>;
					hysteresis = <0x3e8>;
					type = "active";
					linux,phandle = <0x14a>;
					phandle = <0x14a>;
				};

				atlas1-alert-5 {
					temperature = <0x15f90>;
					hysteresis = <0x3e8>;
					type = "active";
					linux,phandle = <0x14b>;
					phandle = <0x14b>;
				};

				atlas1-alert-6 {
					temperature = <0x17318>;
					hysteresis = <0x3e8>;
					type = "active";
					linux,phandle = <0x14c>;
					phandle = <0x14c>;
				};
			};
		};

		g3d-thermal {
			thermal-sensors = <0x8d>;
			polling-delay-passive = <0x0>;
			polling-delay = <0x0>;
			linux,phandle = <0x14d>;
			phandle = <0x14d>;

			trips {

				g3d-alert-0 {
					temperature = <0x11170>;
					hysteresis = <0x3e8>;
					type = "active";
					linux,phandle = <0x14e>;
					phandle = <0x14e>;
				};

				g3d-alert-1 {
					temperature = <0x124f8>;
					hysteresis = <0x3e8>;
					type = "active";
					linux,phandle = <0x14f>;
					phandle = <0x14f>;
				};

				g3d-alert-2 {
					temperature = <0x13880>;
					hysteresis = <0x3e8>;
					type = "active";
					linux,phandle = <0x150>;
					phandle = <0x150>;
				};

				g3d-alert-3 {
					temperature = <0x14c08>;
					hysteresis = <0x3e8>;
					type = "active";
					linux,phandle = <0x151>;
					phandle = <0x151>;
				};

				g3d-alert-4 {
					temperature = <0x15f90>;
					hysteresis = <0x3e8>;
					type = "active";
					linux,phandle = <0x152>;
					phandle = <0x152>;
				};

				g3d-alert-5 {
					temperature = <0x17318>;
					hysteresis = <0x3e8>;
					type = "active";
					linux,phandle = <0x153>;
					phandle = <0x153>;
				};

				g3d-alert-6 {
					temperature = <0x186a0>;
					hysteresis = <0x3e8>;
					type = "active";
					linux,phandle = <0x154>;
					phandle = <0x154>;
				};
			};
		};

		apollo-thermal {
			thermal-sensors = <0x8e>;
			polling-delay-passive = <0x0>;
			polling-delay = <0x0>;
			linux,phandle = <0x155>;
			phandle = <0x155>;

			trips {

				apollo-alert-0 {
					temperature = <0xfde8>;
					hysteresis = <0x3e8>;
					type = "active";
					linux,phandle = <0x156>;
					phandle = <0x156>;
				};

				apollo-alert-1 {
					temperature = <0x11170>;
					hysteresis = <0x3e8>;
					type = "active";
					linux,phandle = <0x157>;
					phandle = <0x157>;
				};

				apollo-alert-2 {
					temperature = <0x124f8>;
					hysteresis = <0x3e8>;
					type = "active";
					linux,phandle = <0x8f>;
					phandle = <0x8f>;
				};

				apollo-alert-3 {
					temperature = <0x13880>;
					hysteresis = <0x3e8>;
					type = "active";
					linux,phandle = <0x91>;
					phandle = <0x91>;
				};

				apollo-alert-4 {
					temperature = <0x14c08>;
					hysteresis = <0x3e8>;
					type = "active";
					linux,phandle = <0x92>;
					phandle = <0x92>;
				};

				apollo-alert-5 {
					temperature = <0x15f90>;
					hysteresis = <0x3e8>;
					type = "active";
					linux,phandle = <0x93>;
					phandle = <0x93>;
				};

				apollo-alert-6 {
					temperature = <0x17318>;
					hysteresis = <0x3e8>;
					type = "active";
					linux,phandle = <0x94>;
					phandle = <0x94>;
				};
			};

			cooling-maps {

				map0 {
					trip = <0x8f>;
					cooling-device = <0x90 0x1 0x2>;
				};

				map1 {
					trip = <0x91>;
					cooling-device = <0x90 0x2 0x3>;
				};

				map2 {
					trip = <0x92>;
					cooling-device = <0x90 0x3 0x4>;
				};

				map3 {
					trip = <0x93>;
					cooling-device = <0x90 0x4 0x5>;
				};

				map4 {
					trip = <0x94>;
					cooling-device = <0x90 0x5 0x9>;
				};
			};
		};

		isp-thermal {
			thermal-sensors = <0x95>;
			polling-delay-passive = <0x0>;
			polling-delay = <0x0>;
			linux,phandle = <0x158>;
			phandle = <0x158>;

			trips {

				isp-alert-0 {
					temperature = <0x13880>;
					hysteresis = <0x3e8>;
					type = "active";
					linux,phandle = <0x159>;
					phandle = <0x159>;
				};

				isp-alert-1 {
					temperature = <0x14c08>;
					hysteresis = <0x3e8>;
					type = "active";
					linux,phandle = <0x15a>;
					phandle = <0x15a>;
				};

				isp-alert-2 {
					temperature = <0x15f90>;
					hysteresis = <0x3e8>;
					type = "active";
					linux,phandle = <0x15b>;
					phandle = <0x15b>;
				};

				isp-alert-3 {
					temperature = <0x17318>;
					hysteresis = <0x3e8>;
					type = "active";
					linux,phandle = <0x15c>;
					phandle = <0x15c>;
				};

				isp-alert-4 {
					temperature = <0x186a0>;
					hysteresis = <0x3e8>;
					type = "active";
					linux,phandle = <0x15d>;
					phandle = <0x15d>;
				};

				isp-alert-5 {
					temperature = <0x19a28>;
					hysteresis = <0x3e8>;
					type = "active";
					linux,phandle = <0x15e>;
					phandle = <0x15e>;
				};

				isp-alert-6 {
					temperature = <0x1adb0>;
					hysteresis = <0x3e8>;
					type = "active";
					linux,phandle = <0x15f>;
					phandle = <0x15f>;
				};
			};
		};
	};

	aliases {
		gsc0 = "/soc/video-scaler@13C00000";
		gsc1 = "/soc/video-scaler@13C10000";
		gsc2 = "/soc/video-scaler@13C20000";
		pinctrl0 = "/soc/pinctrl@10580000";
		pinctrl1 = "/soc/pinctrl@114b0000";
		pinctrl2 = "/soc/pinctrl@10fe0000";
		pinctrl3 = "/soc/pinctrl@14ca0000";
		pinctrl4 = "/soc/pinctrl@14cb0000";
		pinctrl5 = "/soc/pinctrl@15690000";
		pinctrl6 = "/soc/pinctrl@11090000";
		pinctrl7 = "/soc/pinctrl@14cd0000";
		pinctrl8 = "/soc/pinctrl@14cc0000";
		pinctrl9 = "/soc/pinctrl@14ce0000";
		serial0 = "/soc/serial@14c10000";
		serial1 = "/soc/serial@14c20000";
		serial2 = "/soc/serial@14c30000";
		serial3 = "/soc/audio-subsystem@11400000/serial@11460000";
		spi0 = "/soc/spi@14d20000";
		spi1 = "/soc/spi@14d30000";
		spi2 = "/soc/spi@14d40000";
		spi3 = "/soc/spi@14d50000";
		spi4 = "/soc/spi@14d00000";
		mshc0 = "/soc/mshc@15540000";
		mshc2 = "/soc/mshc@15560000";
	};

	chosen {
		stdout-path = "/soc/serial@14c20000";
	};

	memory@20000000 {
		device_type = "memory";
		reg = <0x0 0x20000000 0x0 0xc0000000>;
	};

	gpio-keys {
		compatible = "gpio-keys";

		power-key {
			gpios = <0x72 0x7 0x1>;
			linux,code = <0x74>;
			label = "power key";
			debounce-interval = <0xa>;
		};

		volume-up-key {
			gpios = <0x72 0x0 0x1>;
			linux,code = <0x73>;
			label = "volume-up key";
			debounce-interval = <0xa>;
		};

		volume-down-key {
			gpios = <0x72 0x1 0x1>;
			linux,code = <0x72>;
			label = "volume-down key";
			debounce-interval = <0xa>;
		};

		homepage-key {
			gpios = <0x44 0x3 0x1>;
			linux,code = <0x8b>;
			label = "homepage key";
			debounce-interval = <0xa>;
		};
	};

	i2c-gpio-0 {
		compatible = "i2c-gpio";
		gpios = <0x96 0x1 0x0 0x96 0x0 0x0>;
		i2c-gpio,delay-us = <0x2>;
		#address-cells = <0x1>;
		#size-cells = <0x0>;
		status = "okay";
		linux,phandle = <0x160>;
		phandle = <0x160>;

		max98504@31 {
			compatible = "maxim,max98504";
			reg = <0x31>;
			maxim,rx-path = <0x1>;
			maxim,tx-path = <0x1>;
			maxim,tx-channel-mask = <0x3>;
			maxim,tx-channel-source = <0x2>;
			linux,phandle = <0x9a>;
			phandle = <0x9a>;
		};
	};

	irda-regulator {
		compatible = "regulator-fixed";
		enable-active-high;
		gpio = <0x97 0x3 0x0>;
		regulator-name = "irda_regulator";
		linux,phandle = <0x4b>;
		phandle = <0x4b>;
	};

	sound {
		compatible = "samsung,tm2-audio";
		audio-codec = <0x98>;
		i2s-controller = <0x99>;
		audio-amplifier = <0x9a>;
		mic-bias-gpios = <0x97 0x2 0x0>;
		model = "wm5110";
		samsung,audio-routing = "HP", "HPOUT1L", "HP", "HPOUT1R", "SPK", "SPKOUT", "SPKOUT", "HPOUT2L", "SPKOUT", "HPOUT2R", "RCV", "HPOUT3L", "RCV", "HPOUT3R";
		status = "okay";
	};

	__symbols__ {
		cpu0 = "/cpus/cpu@100";
		cpu1 = "/cpus/cpu@101";
		cpu2 = "/cpus/cpu@102";
		cpu3 = "/cpus/cpu@103";
		cpu4 = "/cpus/cpu@0";
		cpu5 = "/cpus/cpu@1";
		cpu6 = "/cpus/cpu@2";
		cpu7 = "/cpus/cpu@3";
		cluster_a53_opp_table = "/opp_table0";
		cluster_a57_opp_table = "/opp_table1";
		reboot = "/syscon-reboot";
		soc = "/soc";
		xxti = "/soc/xxti";
		cmu_top = "/soc/clock-controller@10030000";
		cmu_cpif = "/soc/clock-controller@10fc0000";
		cmu_mif = "/soc/clock-controller@105b0000";
		cmu_peric = "/soc/clock-controller@14c80000";
		cmu_peris = "/soc/clock-controller@10040000";
		cmu_fsys = "/soc/clock-controller@156e0000";
		cmu_g2d = "/soc/clock-controller@12460000";
		cmu_disp = "/soc/clock-controller@13b90000";
		cmu_aud = "/soc/clock-controller@114c0000";
		cmu_bus0 = "/soc/clock-controller@13600000";
		cmu_bus1 = "/soc/clock-controller@14800000";
		cmu_bus2 = "/soc/clock-controller@13400000";
		cmu_g3d = "/soc/clock-controller@14aa0000";
		cmu_gscl = "/soc/clock-controller@13cf0000";
		cmu_apollo = "/soc/clock-controller@11900000";
		cmu_atlas = "/soc/clock-controller@11800000";
		cmu_mscl = "/soc/clock-controller@105d0000";
		cmu_mfc = "/soc/clock-controller@15280000";
		cmu_hevc = "/soc/clock-controller@14f80000";
		cmu_isp = "/soc/clock-controller@146d0000";
		cmu_cam0 = "/soc/clock-controller@120d0000";
		cmu_cam1 = "/soc/clock-controller@145d0000";
		tmu_atlas0 = "/soc/tmu@10060000";
		tmu_atlas1 = "/soc/tmu@10068000";
		tmu_g3d = "/soc/tmu@10070000";
		tmu_apollo = "/soc/tmu@10078000";
		tmu_isp = "/soc/tmu@1007c000";
		ppmu_d0_cpu = "/soc/ppmu@10480000";
		ppmu_d0_general = "/soc/ppmu@10490000";
		ppmu_event0_d0_general = "/soc/ppmu@10490000/events/ppmu-event0-d0-general";
		ppmu_d1_cpu = "/soc/ppmu@104b0000";
		ppmu_d1_general = "/soc/ppmu@104c0000";
		ppmu_event0_d1_general = "/soc/ppmu@104c0000/events/ppmu-event0-d1-general";
		pinctrl_alive = "/soc/pinctrl@10580000";
		gpa0 = "/soc/pinctrl@10580000/gpa0";
		gpa1 = "/soc/pinctrl@10580000/gpa1";
		gpa2 = "/soc/pinctrl@10580000/gpa2";
		gpa3 = "/soc/pinctrl@10580000/gpa3";
		gpf1 = "/soc/pinctrl@10580000/gpf1";
		gpf2 = "/soc/pinctrl@10580000/gpf2";
		gpf3 = "/soc/pinctrl@10580000/gpf3";
		gpf4 = "/soc/pinctrl@10580000/gpf4";
		gpf5 = "/soc/pinctrl@10580000/gpf5";
		initial_alive = "/soc/pinctrl@10580000/initial-state";
		te_irq = "/soc/pinctrl@10580000/te_irq";
		pinctrl_aud = "/soc/pinctrl@114b0000";
		gpz0 = "/soc/pinctrl@114b0000/gpz0";
		gpz1 = "/soc/pinctrl@114b0000/gpz1";
		i2s0_bus = "/soc/pinctrl@114b0000/i2s0-bus";
		pcm0_bus = "/soc/pinctrl@114b0000/pcm0-bus";
		uart_aud_bus = "/soc/pinctrl@114b0000/uart-aud-bus";
		pinctrl_cpif = "/soc/pinctrl@10fe0000";
		gpv6 = "/soc/pinctrl@10fe0000/gpv6";
		initial_cpif = "/soc/pinctrl@10fe0000/initial-state";
		pinctrl_ese = "/soc/pinctrl@14ca0000";
		gpj2 = "/soc/pinctrl@14ca0000/gpj2";
		initial_ese = "/soc/pinctrl@14ca0000/initial-state";
		pinctrl_finger = "/soc/pinctrl@14cb0000";
		gpd5 = "/soc/pinctrl@14cb0000/gpd5";
		spi2_bus = "/soc/pinctrl@14cb0000/spi2-bus";
		hs_i2c6_bus = "/soc/pinctrl@14cb0000/hs-i2c6-bus";
		pinctrl_fsys = "/soc/pinctrl@15690000";
		gph1 = "/soc/pinctrl@15690000/gph1";
		gpr4 = "/soc/pinctrl@15690000/gpr4";
		gpr0 = "/soc/pinctrl@15690000/gpr0";
		gpr1 = "/soc/pinctrl@15690000/gpr1";
		gpr2 = "/soc/pinctrl@15690000/gpr2";
		gpr3 = "/soc/pinctrl@15690000/gpr3";
		sd0_clk = "/soc/pinctrl@15690000/sd0-clk";
		sd0_cmd = "/soc/pinctrl@15690000/sd0-cmd";
		sd0_rdqs = "/soc/pinctrl@15690000/sd0-rdqs";
		sd0_qrdy = "/soc/pinctrl@15690000/sd0-qrdy";
		sd0_bus1 = "/soc/pinctrl@15690000/sd0-bus-width1";
		sd0_bus4 = "/soc/pinctrl@15690000/sd0-bus-width4";
		sd0_bus8 = "/soc/pinctrl@15690000/sd0-bus-width8";
		sd1_clk = "/soc/pinctrl@15690000/sd1-clk";
		sd1_cmd = "/soc/pinctrl@15690000/sd1-cmd";
		sd1_bus1 = "/soc/pinctrl@15690000/sd1-bus-width1";
		sd1_bus4 = "/soc/pinctrl@15690000/sd1-bus-width4";
		sd1_bus8 = "/soc/pinctrl@15690000/sd1-bus-width8";
		pcie_bus = "/soc/pinctrl@15690000/pcie_bus";
		sd2_clk = "/soc/pinctrl@15690000/sd2-clk";
		sd2_cmd = "/soc/pinctrl@15690000/sd2-cmd";
		sd2_cd = "/soc/pinctrl@15690000/sd2-cd";
		sd2_bus1 = "/soc/pinctrl@15690000/sd2-bus-width1";
		sd2_bus4 = "/soc/pinctrl@15690000/sd2-bus-width4";
		sd2_clk_output = "/soc/pinctrl@15690000/sd2-clk-output";
		sd2_cmd_output = "/soc/pinctrl@15690000/sd2-cmd-output";
		initial_fsys = "/soc/pinctrl@15690000/initial-state";
		pinctrl_imem = "/soc/pinctrl@11090000";
		gpf0 = "/soc/pinctrl@11090000/gpf0";
		initial_imem = "/soc/pinctrl@11090000/initial-state";
		pinctrl_nfc = "/soc/pinctrl@14cd0000";
		gpj0 = "/soc/pinctrl@14cd0000/gpj0";
		hs_i2c4_bus = "/soc/pinctrl@14cd0000/hs-i2c4-bus";
		initial_nfc = "/soc/pinctrl@14cd0000/initial-state";
		pinctrl_peric = "/soc/pinctrl@14cc0000";
		gpv7 = "/soc/pinctrl@14cc0000/gpv7";
		gpb0 = "/soc/pinctrl@14cc0000/gpb0";
		gpc0 = "/soc/pinctrl@14cc0000/gpc0";
		gpc1 = "/soc/pinctrl@14cc0000/gpc1";
		gpc2 = "/soc/pinctrl@14cc0000/gpc2";
		gpc3 = "/soc/pinctrl@14cc0000/gpc3";
		gpg0 = "/soc/pinctrl@14cc0000/gpg0";
		gpd0 = "/soc/pinctrl@14cc0000/gpd0";
		gpd1 = "/soc/pinctrl@14cc0000/gpd1";
		gpd2 = "/soc/pinctrl@14cc0000/gpd2";
		gpd4 = "/soc/pinctrl@14cc0000/gpd4";
		gpd8 = "/soc/pinctrl@14cc0000/gpd8";
		gpd6 = "/soc/pinctrl@14cc0000/gpd6";
		gpd7 = "/soc/pinctrl@14cc0000/gpd7";
		gpg1 = "/soc/pinctrl@14cc0000/gpg1";
		gpg2 = "/soc/pinctrl@14cc0000/gpg2";
		gpg3 = "/soc/pinctrl@14cc0000/gpg3";
		hs_i2c8_bus = "/soc/pinctrl@14cc0000/hs-i2c8-bus";
		hs_i2c9_bus = "/soc/pinctrl@14cc0000/hs-i2c9-bus";
		i2s1_bus = "/soc/pinctrl@14cc0000/i2s1-bus";
		pcm1_bus = "/soc/pinctrl@14cc0000/pcm1-bus";
		spdif_bus = "/soc/pinctrl@14cc0000/spdif-bus";
		fimc_is_spi_pin0 = "/soc/pinctrl@14cc0000/fimc-is-spi-pin0";
		fimc_is_spi_pin1 = "/soc/pinctrl@14cc0000/fimc-is-spi-pin1";
		uart0_bus = "/soc/pinctrl@14cc0000/uart0-bus";
		hs_i2c2_bus = "/soc/pinctrl@14cc0000/hs-i2c2-bus";
		uart2_bus = "/soc/pinctrl@14cc0000/uart2-bus";
		uart1_bus = "/soc/pinctrl@14cc0000/uart1-bus";
		hs_i2c3_bus = "/soc/pinctrl@14cc0000/hs-i2c3-bus";
		hs_i2c0_bus = "/soc/pinctrl@14cc0000/hs-i2c0-bus";
		hs_i2c1_bus = "/soc/pinctrl@14cc0000/hs-i2c1-bus";
		pwm0_out = "/soc/pinctrl@14cc0000/pwm0-out";
		pwm1_out = "/soc/pinctrl@14cc0000/pwm1-out";
		pwm2_out = "/soc/pinctrl@14cc0000/pwm2-out";
		pwm3_out = "/soc/pinctrl@14cc0000/pwm3-out";
		spi1_bus = "/soc/pinctrl@14cc0000/spi1-bus";
		hs_i2c7_bus = "/soc/pinctrl@14cc0000/hs-i2c7-bus";
		spi0_bus = "/soc/pinctrl@14cc0000/spi0-bus";
		hs_i2c10_bus = "/soc/pinctrl@14cc0000/hs-i2c10-bus";
		hs_i2c11_bus = "/soc/pinctrl@14cc0000/hs-i2c11-bus";
		spi3_bus = "/soc/pinctrl@14cc0000/spi3-bus";
		spi4_bus = "/soc/pinctrl@14cc0000/spi4-bus";
		fimc_is_uart = "/soc/pinctrl@14cc0000/fimc-is-uart";
		fimc_is_ch0_i2c = "/soc/pinctrl@14cc0000/fimc-is-ch0_i2c";
		fimc_is_ch0_mclk = "/soc/pinctrl@14cc0000/fimc-is-ch0_mclk";
		fimc_is_ch1_i2c = "/soc/pinctrl@14cc0000/fimc-is-ch1-i2c";
		fimc_is_ch1_mclk = "/soc/pinctrl@14cc0000/fimc-is-ch1-mclk";
		fimc_is_ch2_i2c = "/soc/pinctrl@14cc0000/fimc-is-ch2-i2c";
		fimc_is_ch2_mclk = "/soc/pinctrl@14cc0000/fimc-is-ch2-mclk";
		initial_peric = "/soc/pinctrl@14cc0000/initial-state";
		pinctrl_touch = "/soc/pinctrl@14ce0000";
		gpj1 = "/soc/pinctrl@14ce0000/gpj1";
		hs_i2c5_bus = "/soc/pinctrl@14ce0000/hs-i2c5-bus";
		initial_touch = "/soc/pinctrl@14ce0000/initial-state";
		pmu_system_controller = "/soc/system-controller@105c0000";
		gic = "/soc/interrupt-controller@11001000";
		mipi_phy = "/soc/video-phy";
		decon = "/soc/decon@13800000";
		decon_to_mic = "/soc/decon@13800000/ports/port@0/endpoint";
		decon_tv = "/soc/decon@13880000";
		tv_to_hdmi = "/soc/decon@13880000/ports/port@0/endpoint";
		dsi = "/soc/dsi@13900000";
		dsi_to_mic = "/soc/dsi@13900000/ports/port@0/endpoint";
		mic = "/soc/mic@13930000";
		mic_to_decon = "/soc/mic@13930000/ports/port@0/endpoint";
		mic_to_dsi = "/soc/mic@13930000/ports/port@1/endpoint";
		hdmi = "/soc/hdmi@13970000";
		hdmi_to_tv = "/soc/hdmi@13970000/ports/port@0/endpoint";
		hdmi_to_mhl = "/soc/hdmi@13970000/ports/port@1/endpoint";
		hdmiphy = "/soc/hdmiphy@13af0000";
		syscon_disp = "/soc/syscon@13b80000";
		syscon_cam0 = "/soc/syscon@120f0000";
		syscon_cam1 = "/soc/syscon@145f0000";
		gsc_0 = "/soc/video-scaler@13C00000";
		gsc_1 = "/soc/video-scaler@13C10000";
		gsc_2 = "/soc/video-scaler@13C20000";
		jpeg = "/soc/codec@15020000";
		mfc = "/soc/codec@152E0000";
		sysmmu_decon0x = "/soc/sysmmu@13a00000";
		sysmmu_decon1x = "/soc/sysmmu@13a10000";
		sysmmu_tv0x = "/soc/sysmmu@13a20000";
		sysmmu_tv1x = "/soc/sysmmu@13a30000";
		sysmmu_gscl0 = "/soc/sysmmu@13c80000";
		sysmmu_gscl1 = "/soc/sysmmu@13c90000";
		sysmmu_gscl2 = "/soc/sysmmu@13ca0000";
		sysmmu_jpeg = "/soc/sysmmu@15060000";
		sysmmu_mfc_0 = "/soc/sysmmu@15200000";
		sysmmu_mfc_1 = "/soc/sysmmu@15210000";
		serial_0 = "/soc/serial@14c10000";
		serial_1 = "/soc/serial@14c20000";
		serial_2 = "/soc/serial@14c30000";
		spi_0 = "/soc/spi@14d20000";
		spi_1 = "/soc/spi@14d30000";
		wm5110 = "/soc/spi@14d30000/wm5110-codec@0";
		spi_2 = "/soc/spi@14d40000";
		spi_3 = "/soc/spi@14d50000";
		spi_4 = "/soc/spi@14d00000";
		adc = "/soc/adc@14d10000";
		pwm = "/soc/pwm@14dd0000";
		hsi2c_0 = "/soc/hsi2c@14e40000";
		s2mps13_osc = "/soc/hsi2c@14e40000/s2mps13-pmic@66/clocks";
		ldo1_reg = "/soc/hsi2c@14e40000/s2mps13-pmic@66/regulators/LDO1";
		ldo2_reg = "/soc/hsi2c@14e40000/s2mps13-pmic@66/regulators/LDO2";
		ldo3_reg = "/soc/hsi2c@14e40000/s2mps13-pmic@66/regulators/LDO3";
		ldo4_reg = "/soc/hsi2c@14e40000/s2mps13-pmic@66/regulators/LDO4";
		ldo5_reg = "/soc/hsi2c@14e40000/s2mps13-pmic@66/regulators/LDO5";
		ldo6_reg = "/soc/hsi2c@14e40000/s2mps13-pmic@66/regulators/LDO6";
		ldo7_reg = "/soc/hsi2c@14e40000/s2mps13-pmic@66/regulators/LDO7";
		ldo8_reg = "/soc/hsi2c@14e40000/s2mps13-pmic@66/regulators/LDO8";
		ldo9_reg = "/soc/hsi2c@14e40000/s2mps13-pmic@66/regulators/LDO9";
		ldo10_reg = "/soc/hsi2c@14e40000/s2mps13-pmic@66/regulators/LDO10";
		ldo11_reg = "/soc/hsi2c@14e40000/s2mps13-pmic@66/regulators/LDO11";
		ldo12_reg = "/soc/hsi2c@14e40000/s2mps13-pmic@66/regulators/LDO12";
		ldo13_reg = "/soc/hsi2c@14e40000/s2mps13-pmic@66/regulators/LDO13";
		ldo14_reg = "/soc/hsi2c@14e40000/s2mps13-pmic@66/regulators/LDO14";
		ldo15_reg = "/soc/hsi2c@14e40000/s2mps13-pmic@66/regulators/LDO15";
		ldo16_reg = "/soc/hsi2c@14e40000/s2mps13-pmic@66/regulators/LDO16";
		ldo17_reg = "/soc/hsi2c@14e40000/s2mps13-pmic@66/regulators/LDO17";
		ldo18_reg = "/soc/hsi2c@14e40000/s2mps13-pmic@66/regulators/LDO18";
		ldo19_reg = "/soc/hsi2c@14e40000/s2mps13-pmic@66/regulators/LDO19";
		ldo20_reg = "/soc/hsi2c@14e40000/s2mps13-pmic@66/regulators/LDO20";
		ldo21_reg = "/soc/hsi2c@14e40000/s2mps13-pmic@66/regulators/LDO21";
		ldo22_reg = "/soc/hsi2c@14e40000/s2mps13-pmic@66/regulators/LDO22";
		ldo23_reg = "/soc/hsi2c@14e40000/s2mps13-pmic@66/regulators/LDO23";
		ldo24_reg = "/soc/hsi2c@14e40000/s2mps13-pmic@66/regulators/LDO24";
		ldo25_reg = "/soc/hsi2c@14e40000/s2mps13-pmic@66/regulators/LDO25";
		ldo26_reg = "/soc/hsi2c@14e40000/s2mps13-pmic@66/regulators/LDO26";
		ldo27_reg = "/soc/hsi2c@14e40000/s2mps13-pmic@66/regulators/LDO27";
		ldo28_reg = "/soc/hsi2c@14e40000/s2mps13-pmic@66/regulators/LDO28";
		ldo29_reg = "/soc/hsi2c@14e40000/s2mps13-pmic@66/regulators/LDO29";
		ldo30_reg = "/soc/hsi2c@14e40000/s2mps13-pmic@66/regulators/LDO30";
		ldo31_reg = "/soc/hsi2c@14e40000/s2mps13-pmic@66/regulators/LDO31";
		ldo32_reg = "/soc/hsi2c@14e40000/s2mps13-pmic@66/regulators/LDO32";
		ldo33_reg = "/soc/hsi2c@14e40000/s2mps13-pmic@66/regulators/LDO33";
		ldo34_reg = "/soc/hsi2c@14e40000/s2mps13-pmic@66/regulators/LDO34";
		ldo35_reg = "/soc/hsi2c@14e40000/s2mps13-pmic@66/regulators/LDO35";
		ldo36_reg = "/soc/hsi2c@14e40000/s2mps13-pmic@66/regulators/LDO36";
		ldo37_reg = "/soc/hsi2c@14e40000/s2mps13-pmic@66/regulators/LDO37";
		ldo38_reg = "/soc/hsi2c@14e40000/s2mps13-pmic@66/regulators/LDO38";
		ldo39_reg = "/soc/hsi2c@14e40000/s2mps13-pmic@66/regulators/LDO39";
		ldo40_reg = "/soc/hsi2c@14e40000/s2mps13-pmic@66/regulators/LDO40";
		buck1_reg = "/soc/hsi2c@14e40000/s2mps13-pmic@66/regulators/BUCK1";
		buck2_reg = "/soc/hsi2c@14e40000/s2mps13-pmic@66/regulators/BUCK2";
		buck3_reg = "/soc/hsi2c@14e40000/s2mps13-pmic@66/regulators/BUCK3";
		buck4_reg = "/soc/hsi2c@14e40000/s2mps13-pmic@66/regulators/BUCK4";
		buck5_reg = "/soc/hsi2c@14e40000/s2mps13-pmic@66/regulators/BUCK5";
		buck6_reg = "/soc/hsi2c@14e40000/s2mps13-pmic@66/regulators/BUCK6";
		buck7_reg = "/soc/hsi2c@14e40000/s2mps13-pmic@66/regulators/BUCK7";
		buck8_reg = "/soc/hsi2c@14e40000/s2mps13-pmic@66/regulators/BUCK8";
		buck9_reg = "/soc/hsi2c@14e40000/s2mps13-pmic@66/regulators/BUCK9";
		buck10_reg = "/soc/hsi2c@14e40000/s2mps13-pmic@66/regulators/BUCK10";
		hsi2c_1 = "/soc/hsi2c@14e50000";
		hsi2c_2 = "/soc/hsi2c@14e60000";
		hsi2c_3 = "/soc/hsi2c@14e70000";
		hsi2c_4 = "/soc/hsi2c@14ec0000";
		hsi2c_5 = "/soc/hsi2c@14ed0000";
		stmfts = "/soc/hsi2c@14ed0000/touchscreen@49";
		hsi2c_6 = "/soc/hsi2c@14ee0000";
		hsi2c_7 = "/soc/hsi2c@14ef0000";
		mhl_to_hdmi = "/soc/hsi2c@14ef0000/sii8620@39/port/endpoint";
		hsi2c_8 = "/soc/hsi2c@14d90000";
		muic = "/soc/hsi2c@14d90000/max77843@66/max77843-muic";
		safeout1_reg = "/soc/hsi2c@14d90000/max77843@66/regulators/SAFEOUT1";
		safeout2_reg = "/soc/hsi2c@14d90000/max77843@66/regulators/SAFEOUT2";
		charger_reg = "/soc/hsi2c@14d90000/max77843@66/regulators/CHARGER";
		haptic = "/soc/hsi2c@14d90000/max77843@66/max77843-haptic";
		hsi2c_9 = "/soc/hsi2c@14da0000";
		hsi2c_10 = "/soc/hsi2c@14de0000";
		hsi2c_11 = "/soc/hsi2c@14df0000";
		usbdrd30 = "/soc/usbdrd";
		usbdrd_dwc3 = "/soc/usbdrd/dwc3@15400000";
		usbdrd30_phy = "/soc/phy@15500000";
		usbhost30_phy = "/soc/phy@15580000";
		usbhost30 = "/soc/usbhost";
		usbhost_dwc3 = "/soc/usbhost/dwc3@15a00000";
		mshc_0 = "/soc/mshc@15540000";
		mshc_1 = "/soc/mshc@15550000";
		mshc_2 = "/soc/mshc@15560000";
		pdma0 = "/soc/amba/pdma@15610000";
		pdma1 = "/soc/amba/pdma@15600000";
		adma = "/soc/audio-subsystem@11400000/adma@11420000";
		i2s0 = "/soc/audio-subsystem@11400000/i2s0@11440000";
		serial_3 = "/soc/audio-subsystem@11400000/serial@11460000";
		bus_g2d_400 = "/soc/bus0";
		bus_g2d_266 = "/soc/bus1";
		bus_gscl = "/soc/bus2";
		bus_hevc = "/soc/bus3";
		bus_jpeg = "/soc/bus4";
		bus_mfc = "/soc/bus5";
		bus_mscl = "/soc/bus6";
		bus_noc0 = "/soc/bus7";
		bus_noc1 = "/soc/bus8";
		bus_noc2 = "/soc/bus9";
		bus_g2d_400_opp_table = "/soc/opp_table2";
		bus_g2d_266_opp_table = "/soc/opp_table3";
		bus_gscl_opp_table = "/soc/opp_table4";
		bus_hevc_opp_table = "/soc/opp_table5";
		bus_noc2_opp_table = "/soc/opp_table6";
		timer = "/timer";
		atlas0_thermal = "/thermal-zones/atlas0-thermal";
		atlas0_alert_0 = "/thermal-zones/atlas0-thermal/trips/atlas0-alert-0";
		atlas0_alert_1 = "/thermal-zones/atlas0-thermal/trips/atlas0-alert-1";
		atlas0_alert_2 = "/thermal-zones/atlas0-thermal/trips/atlas0-alert-2";
		atlas0_alert_3 = "/thermal-zones/atlas0-thermal/trips/atlas0-alert-3";
		atlas0_alert_4 = "/thermal-zones/atlas0-thermal/trips/atlas0-alert-4";
		atlas0_alert_5 = "/thermal-zones/atlas0-thermal/trips/atlas0-alert-5";
		atlas0_alert_6 = "/thermal-zones/atlas0-thermal/trips/atlas0-alert-6";
		atlas1_thermal = "/thermal-zones/atlas1-thermal";
		atlas1_alert_0 = "/thermal-zones/atlas1-thermal/trips/atlas1-alert-0";
		atlas1_alert_1 = "/thermal-zones/atlas1-thermal/trips/atlas1-alert-1";
		atlas1_alert_2 = "/thermal-zones/atlas1-thermal/trips/atlas1-alert-2";
		atlas1_alert_3 = "/thermal-zones/atlas1-thermal/trips/atlas1-alert-3";
		atlas1_alert_4 = "/thermal-zones/atlas1-thermal/trips/atlas1-alert-4";
		atlas1_alert_5 = "/thermal-zones/atlas1-thermal/trips/atlas1-alert-5";
		atlas1_alert_6 = "/thermal-zones/atlas1-thermal/trips/atlas1-alert-6";
		g3d_thermal = "/thermal-zones/g3d-thermal";
		g3d_alert_0 = "/thermal-zones/g3d-thermal/trips/g3d-alert-0";
		g3d_alert_1 = "/thermal-zones/g3d-thermal/trips/g3d-alert-1";
		g3d_alert_2 = "/thermal-zones/g3d-thermal/trips/g3d-alert-2";
		g3d_alert_3 = "/thermal-zones/g3d-thermal/trips/g3d-alert-3";
		g3d_alert_4 = "/thermal-zones/g3d-thermal/trips/g3d-alert-4";
		g3d_alert_5 = "/thermal-zones/g3d-thermal/trips/g3d-alert-5";
		g3d_alert_6 = "/thermal-zones/g3d-thermal/trips/g3d-alert-6";
		apollo_thermal = "/thermal-zones/apollo-thermal";
		apollo_alert_0 = "/thermal-zones/apollo-thermal/trips/apollo-alert-0";
		apollo_alert_1 = "/thermal-zones/apollo-thermal/trips/apollo-alert-1";
		apollo_alert_2 = "/thermal-zones/apollo-thermal/trips/apollo-alert-2";
		apollo_alert_3 = "/thermal-zones/apollo-thermal/trips/apollo-alert-3";
		apollo_alert_4 = "/thermal-zones/apollo-thermal/trips/apollo-alert-4";
		apollo_alert_5 = "/thermal-zones/apollo-thermal/trips/apollo-alert-5";
		apollo_alert_6 = "/thermal-zones/apollo-thermal/trips/apollo-alert-6";
		isp_thermal = "/thermal-zones/isp-thermal";
		isp_alert_0 = "/thermal-zones/isp-thermal/trips/isp-alert-0";
		isp_alert_1 = "/thermal-zones/isp-thermal/trips/isp-alert-1";
		isp_alert_2 = "/thermal-zones/isp-thermal/trips/isp-alert-2";
		isp_alert_3 = "/thermal-zones/isp-thermal/trips/isp-alert-3";
		isp_alert_4 = "/thermal-zones/isp-thermal/trips/isp-alert-4";
		isp_alert_5 = "/thermal-zones/isp-thermal/trips/isp-alert-5";
		isp_alert_6 = "/thermal-zones/isp-thermal/trips/isp-alert-6";
		i2c_max98504 = "/i2c-gpio-0";
		max98504 = "/i2c-gpio-0/max98504@31";
		irda_regulator = "/irda-regulator";
	};
};
